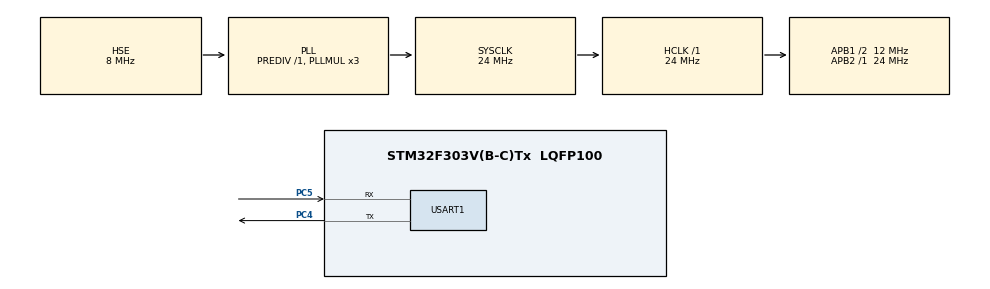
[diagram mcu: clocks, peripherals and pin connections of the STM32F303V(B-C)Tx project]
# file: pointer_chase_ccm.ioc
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Mcu.Family=STM32F3
Mcu.Name=STM32F303V(B-C)Tx
Mcu.Package=LQFP100
NVIC.PriorityGroup=NVIC_PRIORITYGROUP_4
NVIC.TIM2_IRQn=true\:0\:0\:false\:false\:true\:true\:true
PC4.Mode=Asynchronous
PC4.Signal=USART1_TX
PC5.Mode=Asynchronous
PC5.Signal=USART1_RX
PF0-OSC_IN.Mode=HSE-External-Oscillator
PF0-OSC_IN.Signal=RCC_OSC_IN
PF1-OSC_OUT.Mode=HSE-External-Oscillator
PF1-OSC_OUT.Signal=RCC_OSC_OUT
ProjectManager.HeapSize=0x200
ProjectManager.StackSize=0x400
ProjectManager.TargetToolchain=STM32CubeIDE
RCC.AHBFreq_Value=24000000
RCC.APB1CLKDivider=RCC_HCLK_DIV2
RCC.APB1Freq_Value=12000000
RCC.APB1TimFreq_Value=24000000
RCC.APB2Freq_Value=24000000
RCC.APB2TimFreq_Value=24000000
RCC.CortexFreq_Value=24000000
RCC.HCLKFreq_Value=24000000
RCC.HSE_VALUE=8000000
RCC.HSI_VALUE=8000000
RCC.LSE_VALUE=32768
RCC.PLLMUL=RCC_PLL_MUL3
RCC.PLLSourceVirtual=RCC_PLLSOURCE_HSE
RCC.SYSCLKFreq_VALUE=24000000
RCC.SYSCLKSourceVirtual=RCC_SYSCLKSOURCE_PLLCLK
RCC.USBFreq_Value=24000000
TIM2.AutoReloadPreload=TIM_AUTORELOAD_PRELOAD_DISABLE
TIM2.Period=(1000000-1)
TIM2.Prescaler=(24-1)
USART1.VirtualMode-Asynchronous=VM_ASYNC
VP_TIM2_VS_ClockSourceINT.Mode=Internal
board=custom

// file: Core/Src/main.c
/* USER CODE BEGIN Header */
/**
  ******************************************************************************
  * @file           : main.c
  * @brief          : Main program body
  ******************************************************************************
  * @attention
  *
  * <h2><center>&copy; Copyright (c) 2021 STMicroelectronics.
  * All rights reserved.</center></h2>
  *
  * This software component is licensed by ST under BSD 3-Clause license,
  * the "License"; You may not use this file except in compliance with the
  * License. You may obtain a copy of the License at:
  *                        opensource.org/licenses/BSD-3-Clause
  *
  ******************************************************************************
  */
/* USER CODE END Header */
#include "main.h"

/* USER CODE BEGIN PM */
TIM_HandleTypeDef htim2;

UART_HandleTypeDef huart1;

/*data size*/
#define POINTER_SIZE_2000

/*functions data*/
//#define FUNCTIONS_DATA_ON_FLASH
#define FUNCTIONS_DATA_ON_CCM

/*program allocation*/
#define PROGRAM_IN_CCM

/* USER CODE END PM */

TIM_HandleTypeDef htim2;

UART_HandleTypeDef huart1;

/* USER CODE BEGIN PV */
#ifdef PROGRAM_IN_CCM
  __attribute__((section(".ccmram")))
#endif
void pointer_chase( void * p0){

    void **this_pp = p0;
    for(int i = 0;i<1000;i++){
	  while(this_pp){
      this_pp = *this_pp;
	  }
    this_pp = p0;
  };

}

/* USER CODE END PV */

void SystemClock_Config(void);
static void MX_GPIO_Init(void);
static void MX_TIM2_Init(void);
static void MX_USART1_UART_Init(void);

/* USER CODE BEGIN 0 */

#ifdef POINTER_SIZE_100
#ifdef FUNCTIONS_DATA_ON_CCM
  __attribute__((section(".ccmramdata")))
#endif
#ifdef FUNCTIONS_DATA_ON_FLASH
  const
#endif
   void *
#ifdef FUNCTIONS_DATA_ON_FLASH
  const
#endif
  pointers[100] = {
  &pointers[1], &pointers[2], &pointers[3], &pointers[4], &pointers[5], &pointers[6], &pointers[7], &pointers[8], &pointers[9], &pointers[10], &pointers[11], &pointers[12], &pointers[13], &pointers[14], &pointers[15], &pointers[16], &pointers[17], &pointers[18], &pointers[19], &pointers[20], &pointers[21], &pointers[22], &pointers[23], &pointers[24], &pointers[25], &pointers[26], &pointers[27], &pointers[28], &pointers[29], &pointers[30], &pointers[31], &pointers[32], &pointers[33], &pointers[34], &pointers[35], &pointers[36], &pointers[37], &pointers[38], &pointers[39], &pointers[40], &pointers[41], &pointers[42], &pointers[43], &pointers[44], &pointers[45], &pointers[46], &pointers[47], &pointers[48], &pointers[49], &pointers[50],
  &pointers[51], &pointers[52], &pointers[53], &pointers[54], &pointers[55], &pointers[56], &pointers[57], &pointers[58], &pointers[59], &pointers[60], &pointers[61], &pointers[62], &pointers[63], &pointers[64], &pointers[65], &pointers[66], &pointers[67], &pointers[68], &pointers[69], &pointers[70], &pointers[71], &pointers[72], &pointers[73], &pointers[74], &pointers[75], &pointers[76], &pointers[77], &pointers[78], &pointers[79], &pointers[80], &pointers[81], &pointers[82], &pointers[83], &pointers[84], &pointers[85], &pointers[86], &pointers[87], &pointers[88], &pointers[89], &pointers[90], &pointers[91], &pointers[92], &pointers[93], &pointers[94], &pointers[95], &pointers[96], &pointers[97], &pointers[98], &pointers[99], NULL };

#endif

#ifdef POINTER_SIZE_200
#ifdef FUNCTIONS_DATA_ON_CCM
  __attribute__((section(".ccmramdata")))
#endif
#ifdef FUNCTIONS_DATA_ON_FLASH
  const
#endif
   void *
#ifdef FUNCTIONS_DATA_ON_FLASH
  const
#endif
  pointers[200] = {
  &pointers[1], &pointers[2], &pointers[3], &pointers[4], &pointers[5], &pointers[6], &pointers[7], &pointers[8], &pointers[9], &pointers[10], &pointers[11], &pointers[12], &pointers[13], &pointers[14], &pointers[15], &pointers[16], &pointers[17], &pointers[18], &pointers[19], &pointers[20], &pointers[21], &pointers[22], &pointers[23], &pointers[24], &pointers[25], &pointers[26], &pointers[27], &pointers[28], &pointers[29], &pointers[30], &pointers[31], &pointers[32], &pointers[33], &pointers[34], &pointers[35], &pointers[36], &pointers[37], &pointers[38], &pointers[39], &pointers[40], &pointers[41], &pointers[42], &pointers[43], &pointers[44], &pointers[45], &pointers[46], &pointers[47], &pointers[48], &pointers[49], &pointers[50],
  &pointers[51], &pointers[52], &pointers[53], &pointers[54], &pointers[55], &pointers[56], &pointers[57], &pointers[58], &pointers[59], &pointers[60], &pointers[61], &pointers[62], &pointers[63], &pointers[64], &pointers[65], &pointers[66], &pointers[67], &pointers[68], &pointers[69], &pointers[70], &pointers[71], &pointers[72], &pointers[73], &pointers[74], &pointers[75], &pointers[76], &pointers[77], &pointers[78], &pointers[79], &pointers[80], &pointers[81], &pointers[82], &pointers[83], &pointers[84], &pointers[85], &pointers[86], &pointers[87], &pointers[88], &pointers[89], &pointers[90], &pointers[91], &pointers[92], &pointers[93], &pointers[94], &pointers[95], &pointers[96], &pointers[97], &pointers[98], &pointers[99], &pointers[100],
  &pointers[101], &pointers[102], &pointers[103], &pointers[104], &pointers[105], &pointers[106], &pointers[107], &pointers[108], &pointers[109], &pointers[110], &pointers[111], &pointers[112], &pointers[113], &pointers[114], &pointers[115], &pointers[116], &pointers[117], &pointers[118], &pointers[119], &pointers[120], &pointers[121], &pointers[122], &pointers[123], &pointers[124], &pointers[125], &pointers[126], &pointers[127], &pointers[128], &pointers[129], &pointers[130], &pointers[131], &pointers[132], &pointers[133], &pointers[134], &pointers[135], &pointers[136], &pointers[137], &pointers[138], &pointers[139], &pointers[140], &pointers[141], &pointers[142], &pointers[143], &pointers[144], &pointers[145], &pointers[146], &pointers[147], &pointers[148], &pointers[149], &pointers[150],
  &pointers[151], &pointers[152], &pointers[153], &pointers[154], &pointers[155], &pointers[156], &pointers[157], &pointers[158], &pointers[159], &pointers[160], &pointers[161], &pointers[162], &pointers[163], &pointers[164], &pointers[165], &pointers[166], &pointers[167], &pointers[168], &pointers[169], &pointers[170], &pointers[171], &pointers[172], &pointers[173], &pointers[174], &pointers[175], &pointers[176], &pointers[177], &pointers[178], &pointers[179], &pointers[180], &pointers[181], &pointers[182], &pointers[183], &pointers[184], &pointers[185], &pointers[186], &pointers[187], &pointers[188], &pointers[189], &pointers[190], &pointers[191], &pointers[192], &pointers[193], &pointers[194], &pointers[195], &pointers[196], &pointers[197], &pointers[198], &pointers[199], NULL };
#endif

#ifdef POINTER_SIZE_300
#ifdef FUNCTIONS_DATA_ON_CCM
  __attribute__((section(".ccmramdata")))
#endif
#ifdef FUNCTIONS_DATA_ON_FLASH
  const
#endif
   void *
#ifdef FUNCTIONS_DATA_ON_FLASH
  const
#endif
  pointers[300] = {
  &pointers[1], &pointers[2], &pointers[3], &pointers[4], &pointers[5], &pointers[6], &pointers[7], &pointers[8], &pointers[9], &pointers[10], &pointers[11], &pointers[12], &pointers[13], &pointers[14], &pointers[15], &pointers[16], &pointers[17], &pointers[18], &pointers[19], &pointers[20], &pointers[21], &pointers[22], &pointers[23], &pointers[24], &pointers[25], &pointers[26], &pointers[27], &pointers[28], &pointers[29], &pointers[30], &pointers[31], &pointers[32], &pointers[33], &pointers[34], &pointers[35], &pointers[36], &pointers[37], &pointers[38], &pointers[39], &pointers[40], &pointers[41], &pointers[42], &pointers[43], &pointers[44], &pointers[45], &pointers[46], &pointers[47], &pointers[48], &pointers[49], &pointers[50],
  &pointers[51], &pointers[52], &pointers[53], &pointers[54], &pointers[55], &pointers[56], &pointers[57], &pointers[58], &pointers[59], &pointers[60], &pointers[61], &pointers[62], &pointers[63], &pointers[64], &pointers[65], &pointers[66], &pointers[67], &pointers[68], &pointers[69], &pointers[70], &pointers[71], &pointers[72], &pointers[73], &pointers[74], &pointers[75], &pointers[76], &pointers[77], &pointers[78], &pointers[79], &pointers[80], &pointers[81], &pointers[82], &pointers[83], &pointers[84], &pointers[85], &pointers[86], &pointers[87], &pointers[88], &pointers[89], &pointers[90], &pointers[91], &pointers[92], &pointers[93], &pointers[94], &pointers[95], &pointers[96], &pointers[97], &pointers[98], &pointers[99], &pointers[100],
  &pointers[101], &pointers[102], &pointers[103], &pointers[104], &pointers[105], &pointers[106], &pointers[107], &pointers[108], &pointers[109], &pointers[110], &pointers[111], &pointers[112], &pointers[113], &pointers[114], &pointers[115], &pointers[116], &pointers[117], &pointers[118], &pointers[119], &pointers[120], &pointers[121], &pointers[122], &pointers[123], &pointers[124], &pointers[125], &pointers[126], &pointers[127], &pointers[128], &pointers[129], &pointers[130], &pointers[131], &pointers[132], &pointers[133], &pointers[134], &pointers[135], &pointers[136], &pointers[137], &pointers[138], &pointers[139], &pointers[140], &pointers[141], &pointers[142], &pointers[143], &pointers[144], &pointers[145], &pointers[146], &pointers[147], &pointers[148], &pointers[149], &pointers[150],
  &pointers[151], &pointers[152], &pointers[153], &pointers[154], &pointers[155], &pointers[156], &pointers[157], &pointers[158], &pointers[159], &pointers[160], &pointers[161], &pointers[162], &pointers[163], &pointers[164], &pointers[165], &pointers[166], &pointers[167], &pointers[168], &pointers[169], &pointers[170], &pointers[171], &pointers[172], &pointers[173], &pointers[174], &pointers[175], &pointers[176], &pointers[177], &pointers[178], &pointers[179], &pointers[180], &pointers[181], &pointers[182], &pointers[183], &pointers[184], &pointers[185], &pointers[186], &pointers[187], &pointers[188], &pointers[189], &pointers[190], &pointers[191], &pointers[192], &pointers[193], &pointers[194], &pointers[195], &pointers[196], &pointers[197], &pointers[198], &pointers[199], &pointers[200],
  &pointers[201], &pointers[202], &pointers[203], &pointers[204], &pointers[205], &pointers[206], &pointers[207], &pointers[208], &pointers[209], &pointers[210], &pointers[211], &pointers[212], &pointers[213], &pointers[214], &pointers[215], &pointers[216], &pointers[217], &pointers[218], &pointers[219], &pointers[220], &pointers[221], &pointers[222], &pointers[223], &pointers[224], &pointers[225], &pointers[226], &pointers[227], &pointers[228], &pointers[229], &pointers[230], &pointers[231], &pointers[232], &pointers[233], &pointers[234], &pointers[235], &pointers[236], &pointers[237], &pointers[238], &pointers[239], &pointers[240], &pointers[241], &pointers[242], &pointers[243], &pointers[244], &pointers[245], &pointers[246], &pointers[247], &pointers[248], &pointers[249], &pointers[250],
  &pointers[251], &pointers[252], &pointers[253], &pointers[254], &pointers[255], &pointers[256], &pointers[257], &pointers[258], &pointers[259], &pointers[260], &pointers[261], &pointers[262], &pointers[263], &pointers[264], &pointers[265], &pointers[266], &pointers[267], &pointers[268], &pointers[269], &pointers[270], &pointers[271], &pointers[272], &pointers[273], &pointers[274], &pointers[275], &pointers[276], &pointers[277], &pointers[278], &pointers[279], &pointers[280], &pointers[281], &pointers[282], &pointers[283], &pointers[284], &pointers[285], &pointers[286], &pointers[287], &pointers[288], &pointers[289], &pointers[290], &pointers[291], &pointers[292], &pointers[293], &pointers[294], &pointers[295], &pointers[296], &pointers[297], &pointers[298], &pointers[299], NULL };
#endif

#ifdef POINTER_SIZE_400
#ifdef FUNCTIONS_DATA_ON_CCM
  __attribute__((section(".ccmramdata")))
#endif
#ifdef FUNCTIONS_DATA_ON_FLASH
  const
#endif
   void *
#ifdef FUNCTIONS_DATA_ON_FLASH
  const
#endif
  pointers[400] = {
  &pointers[1], &pointers[2], &pointers[3], &pointers[4], &pointers[5], &pointers[6], &pointers[7], &pointers[8], &pointers[9], &pointers[10], &pointers[11], &pointers[12], &pointers[13], &pointers[14], &pointers[15], &pointers[16], &pointers[17], &pointers[18], &pointers[19], &pointers[20], &pointers[21], &pointers[22], &pointers[23], &pointers[24], &pointers[25], &pointers[26], &pointers[27], &pointers[28], &pointers[29], &pointers[30], &pointers[31], &pointers[32], &pointers[33], &pointers[34], &pointers[35], &pointers[36], &pointers[37], &pointers[38], &pointers[39], &pointers[40], &pointers[41], &pointers[42], &pointers[43], &pointers[44], &pointers[45], &pointers[46], &pointers[47], &pointers[48], &pointers[49], &pointers[50],
  &pointers[51], &pointers[52], &pointers[53], &pointers[54], &pointers[55], &pointers[56], &pointers[57], &pointers[58], &pointers[59], &pointers[60], &pointers[61], &pointers[62], &pointers[63], &pointers[64], &pointers[65], &pointers[66], &pointers[67], &pointers[68], &pointers[69], &pointers[70], &pointers[71], &pointers[72], &pointers[73], &pointers[74], &pointers[75], &pointers[76], &pointers[77], &pointers[78], &pointers[79], &pointers[80], &pointers[81], &pointers[82], &pointers[83], &pointers[84], &pointers[85], &pointers[86], &pointers[87], &pointers[88], &pointers[89], &pointers[90], &pointers[91], &pointers[92], &pointers[93], &pointers[94], &pointers[95], &pointers[96], &pointers[97], &pointers[98], &pointers[99], &pointers[100],
  &pointers[101], &pointers[102], &pointers[103], &pointers[104], &pointers[105], &pointers[106], &pointers[107], &pointers[108], &pointers[109], &pointers[110], &pointers[111], &pointers[112], &pointers[113], &pointers[114], &pointers[115], &pointers[116], &pointers[117], &pointers[118], &pointers[119], &pointers[120], &pointers[121], &pointers[122], &pointers[123], &pointers[124], &pointers[125], &pointers[126], &pointers[127], &pointers[128], &pointers[129], &pointers[130], &pointers[131], &pointers[132], &pointers[133], &pointers[134], &pointers[135], &pointers[136], &pointers[137], &pointers[138], &pointers[139], &pointers[140], &pointers[141], &pointers[142], &pointers[143], &pointers[144], &pointers[145], &pointers[146], &pointers[147], &pointers[148], &pointers[149], &pointers[150],
  &pointers[151], &pointers[152], &pointers[153], &pointers[154], &pointers[155], &pointers[156], &pointers[157], &pointers[158], &pointers[159], &pointers[160], &pointers[161], &pointers[162], &pointers[163], &pointers[164], &pointers[165], &pointers[166], &pointers[167], &pointers[168], &pointers[169], &pointers[170], &pointers[171], &pointers[172], &pointers[173], &pointers[174], &pointers[175], &pointers[176], &pointers[177], &pointers[178], &pointers[179], &pointers[180], &pointers[181], &pointers[182], &pointers[183], &pointers[184], &pointers[185], &pointers[186], &pointers[187], &pointers[188], &pointers[189], &pointers[190], &pointers[191], &pointers[192], &pointers[193], &pointers[194], &pointers[195], &pointers[196], &pointers[197], &pointers[198], &pointers[199], &pointers[200],
  &pointers[201], &pointers[202], &pointers[203], &pointers[204], &pointers[205], &pointers[206], &pointers[207], &pointers[208], &pointers[209], &pointers[210], &pointers[211], &pointers[212], &pointers[213], &pointers[214], &pointers[215], &pointers[216], &pointers[217], &pointers[218], &pointers[219], &pointers[220], &pointers[221], &pointers[222], &pointers[223], &pointers[224], &pointers[225], &pointers[226], &pointers[227], &pointers[228], &pointers[229], &pointers[230], &pointers[231], &pointers[232], &pointers[233], &pointers[234], &pointers[235], &pointers[236], &pointers[237], &pointers[238], &pointers[239], &pointers[240], &pointers[241], &pointers[242], &pointers[243], &pointers[244], &pointers[245], &pointers[246], &pointers[247], &pointers[248], &pointers[249], &pointers[250],
  &pointers[251], &pointers[252], &pointers[253], &pointers[254], &pointers[255], &pointers[256], &pointers[257], &pointers[258], &pointers[259], &pointers[260], &pointers[261], &pointers[262], &pointers[263], &pointers[264], &pointers[265], &pointers[266], &pointers[267], &pointers[268], &pointers[269], &pointers[270], &pointers[271], &pointers[272], &pointers[273], &pointers[274], &pointers[275], &pointers[276], &pointers[277], &pointers[278], &pointers[279], &pointers[280], &pointers[281], &pointers[282], &pointers[283], &pointers[284], &pointers[285], &pointers[286], &pointers[287], &pointers[288], &pointers[289], &pointers[290], &pointers[291], &pointers[292], &pointers[293], &pointers[294], &pointers[295], &pointers[296], &pointers[297], &pointers[298], &pointers[299], &pointers[300],
  &pointers[301], &pointers[302], &pointers[303], &pointers[304], &pointers[305], &pointers[306], &pointers[307], &pointers[308], &pointers[309], &pointers[310], &pointers[311], &pointers[312], &pointers[313], &pointers[314], &pointers[315], &pointers[316], &pointers[317], &pointers[318], &pointers[319], &pointers[320], &pointers[321], &pointers[322], &pointers[323], &pointers[324], &pointers[325], &pointers[326], &pointers[327], &pointers[328], &pointers[329], &pointers[330], &pointers[331], &pointers[332], &pointers[333], &pointers[334], &pointers[335], &pointers[336], &pointers[337], &pointers[338], &pointers[339], &pointers[340], &pointers[341], &pointers[342], &pointers[343], &pointers[344], &pointers[345], &pointers[346], &pointers[347], &pointers[348], &pointers[349], &pointers[350],
  &pointers[351], &pointers[352], &pointers[353], &pointers[354], &pointers[355], &pointers[356], &pointers[357], &pointers[358], &pointers[359], &pointers[360], &pointers[361], &pointers[362], &pointers[363], &pointers[364], &pointers[365], &pointers[366], &pointers[367], &pointers[368], &pointers[369], &pointers[370], &pointers[371], &pointers[372], &pointers[373], &pointers[374], &pointers[375], &pointers[376], &pointers[377], &pointers[378], &pointers[379], &pointers[380], &pointers[381], &pointers[382], &pointers[383], &pointers[384], &pointers[385], &pointers[386], &pointers[387], &pointers[388], &pointers[389], &pointers[390], &pointers[391], &pointers[392], &pointers[393], &pointers[394], &pointers[395], &pointers[396], &pointers[397], &pointers[398], &pointers[399], NULL };
#endif

#ifdef POINTER_SIZE_500
#ifdef FUNCTIONS_DATA_ON_CCM
  __attribute__((section(".ccmramdata")))
#endif
#ifdef FUNCTIONS_DATA_ON_FLASH
  const
#endif
   void *
#ifdef FUNCTIONS_DATA_ON_FLASH
  const
#endif
  pointers[500] = {
  &pointers[1], &pointers[2], &pointers[3], &pointers[4], &pointers[5], &pointers[6], &pointers[7], &pointers[8], &pointers[9], &pointers[10], &pointers[11], &pointers[12], &pointers[13], &pointers[14], &pointers[15], &pointers[16], &pointers[17], &pointers[18], &pointers[19], &pointers[20], &pointers[21], &pointers[22], &pointers[23], &pointers[24], &pointers[25], &pointers[26], &pointers[27], &pointers[28], &pointers[29], &pointers[30], &pointers[31], &pointers[32], &pointers[33], &pointers[34], &pointers[35], &pointers[36], &pointers[37], &pointers[38], &pointers[39], &pointers[40], &pointers[41], &pointers[42], &pointers[43], &pointers[44], &pointers[45], &pointers[46], &pointers[47], &pointers[48], &pointers[49], &pointers[50],
  &pointers[51], &pointers[52], &pointers[53], &pointers[54], &pointers[55], &pointers[56], &pointers[57], &pointers[58], &pointers[59], &pointers[60], &pointers[61], &pointers[62], &pointers[63], &pointers[64], &pointers[65], &pointers[66], &pointers[67], &pointers[68], &pointers[69], &pointers[70], &pointers[71], &pointers[72], &pointers[73], &pointers[74], &pointers[75], &pointers[76], &pointers[77], &pointers[78], &pointers[79], &pointers[80], &pointers[81], &pointers[82], &pointers[83], &pointers[84], &pointers[85], &pointers[86], &pointers[87], &pointers[88], &pointers[89], &pointers[90], &pointers[91], &pointers[92], &pointers[93], &pointers[94], &pointers[95], &pointers[96], &pointers[97], &pointers[98], &pointers[99], &pointers[100],
  &pointers[101], &pointers[102], &pointers[103], &pointers[104], &pointers[105], &pointers[106], &pointers[107], &pointers[108], &pointers[109], &pointers[110], &pointers[111], &pointers[112], &pointers[113], &pointers[114], &pointers[115], &pointers[116], &pointers[117], &pointers[118], &pointers[119], &pointers[120], &pointers[121], &pointers[122], &pointers[123], &pointers[124], &pointers[125], &pointers[126], &pointers[127], &pointers[128], &pointers[129], &pointers[130], &pointers[131], &pointers[132], &pointers[133], &pointers[134], &pointers[135], &pointers[136], &pointers[137], &pointers[138], &pointers[139], &pointers[140], &pointers[141], &pointers[142], &pointers[143], &pointers[144], &pointers[145], &pointers[146], &pointers[147], &pointers[148], &pointers[149], &pointers[150],
  &pointers[151], &pointers[152], &pointers[153], &pointers[154], &pointers[155], &pointers[156], &pointers[157], &pointers[158], &pointers[159], &pointers[160], &pointers[161], &pointers[162], &pointers[163], &pointers[164], &pointers[165], &pointers[166], &pointers[167], &pointers[168], &pointers[169], &pointers[170], &pointers[171], &pointers[172], &pointers[173], &pointers[174], &pointers[175], &pointers[176], &pointers[177], &pointers[178], &pointers[179], &pointers[180], &pointers[181], &pointers[182], &pointers[183], &pointers[184], &pointers[185], &pointers[186], &pointers[187], &pointers[188], &pointers[189], &pointers[190], &pointers[191], &pointers[192], &pointers[193], &pointers[194], &pointers[195], &pointers[196], &pointers[197], &pointers[198], &pointers[199], &pointers[200],
  &pointers[201], &pointers[202], &pointers[203], &pointers[204], &pointers[205], &pointers[206], &pointers[207], &pointers[208], &pointers[209], &pointers[210], &pointers[211], &pointers[212], &pointers[213], &pointers[214], &pointers[215], &pointers[216], &pointers[217], &pointers[218], &pointers[219], &pointers[220], &pointers[221], &pointers[222], &pointers[223], &pointers[224], &pointers[225], &pointers[226], &pointers[227], &pointers[228], &pointers[229], &pointers[230], &pointers[231], &pointers[232], &pointers[233], &pointers[234], &pointers[235], &pointers[236], &pointers[237], &pointers[238], &pointers[239], &pointers[240], &pointers[241], &pointers[242], &pointers[243], &pointers[244], &pointers[245], &pointers[246], &pointers[247], &pointers[248], &pointers[249], &pointers[250],
  &pointers[251], &pointers[252], &pointers[253], &pointers[254], &pointers[255], &pointers[256], &pointers[257], &pointers[258], &pointers[259], &pointers[260], &pointers[261], &pointers[262], &pointers[263], &pointers[264], &pointers[265], &pointers[266], &pointers[267], &pointers[268], &pointers[269], &pointers[270], &pointers[271], &pointers[272], &pointers[273], &pointers[274], &pointers[275], &pointers[276], &pointers[277], &pointers[278], &pointers[279], &pointers[280], &pointers[281], &pointers[282], &pointers[283], &pointers[284], &pointers[285], &pointers[286], &pointers[287], &pointers[288], &pointers[289], &pointers[290], &pointers[291], &pointers[292], &pointers[293], &pointers[294], &pointers[295], &pointers[296], &pointers[297], &pointers[298], &pointers[299], &pointers[300],
  &pointers[301], &pointers[302], &pointers[303], &pointers[304], &pointers[305], &pointers[306], &pointers[307], &pointers[308], &pointers[309], &pointers[310], &pointers[311], &pointers[312], &pointers[313], &pointers[314], &pointers[315], &pointers[316], &pointers[317], &pointers[318], &pointers[319], &pointers[320], &pointers[321], &pointers[322], &pointers[323], &pointers[324], &pointers[325], &pointers[326], &pointers[327], &pointers[328], &pointers[329], &pointers[330], &pointers[331], &pointers[332], &pointers[333], &pointers[334], &pointers[335], &pointers[336], &pointers[337], &pointers[338], &pointers[339], &pointers[340], &pointers[341], &pointers[342], &pointers[343], &pointers[344], &pointers[345], &pointers[346], &pointers[347], &pointers[348], &pointers[349], &pointers[350],
  &pointers[351], &pointers[352], &pointers[353], &pointers[354], &pointers[355], &pointers[356], &pointers[357], &pointers[358], &pointers[359], &pointers[360], &pointers[361], &pointers[362], &pointers[363], &pointers[364], &pointers[365], &pointers[366], &pointers[367], &pointers[368], &pointers[369], &pointers[370], &pointers[371], &pointers[372], &pointers[373], &pointers[374], &pointers[375], &pointers[376], &pointers[377], &pointers[378], &pointers[379], &pointers[380], &pointers[381], &pointers[382], &pointers[383], &pointers[384], &pointers[385], &pointers[386], &pointers[387], &pointers[388], &pointers[389], &pointers[390], &pointers[391], &pointers[392], &pointers[393], &pointers[394], &pointers[395], &pointers[396], &pointers[397], &pointers[398], &pointers[399], &pointers[400],
  &pointers[401], &pointers[402], &pointers[403], &pointers[404], &pointers[405], &pointers[406], &pointers[407], &pointers[408], &pointers[409], &pointers[410], &pointers[411], &pointers[412], &pointers[413], &pointers[414], &pointers[415], &pointers[416], &pointers[417], &pointers[418], &pointers[419], &pointers[420], &pointers[421], &pointers[422], &pointers[423], &pointers[424], &pointers[425], &pointers[426], &pointers[427], &pointers[428], &pointers[429], &pointers[430], &pointers[431], &pointers[432], &pointers[433], &pointers[434], &pointers[435], &pointers[436], &pointers[437], &pointers[438], &pointers[439], &pointers[440], &pointers[441], &pointers[442], &pointers[443], &pointers[444], &pointers[445], &pointers[446], &pointers[447], &pointers[448], &pointers[449], &pointers[450],
  &pointers[451], &pointers[452], &pointers[453], &pointers[454], &pointers[455], &pointers[456], &pointers[457], &pointers[458], &pointers[459], &pointers[460], &pointers[461], &pointers[462], &pointers[463], &pointers[464], &pointers[465], &pointers[466], &pointers[467], &pointers[468], &pointers[469], &pointers[470], &pointers[471], &pointers[472], &pointers[473], &pointers[474], &pointers[475], &pointers[476], &pointers[477], &pointers[478], &pointers[479], &pointers[480], &pointers[481], &pointers[482], &pointers[483], &pointers[484], &pointers[485], &pointers[486], &pointers[487], &pointers[488], &pointers[489], &pointers[490], &pointers[491], &pointers[492], &pointers[493], &pointers[494], &pointers[495], &pointers[496], &pointers[497], &pointers[498], &pointers[499], NULL };
#endif

#ifdef POINTER_SIZE_750
#ifdef FUNCTIONS_DATA_ON_CCM
  __attribute__((section(".ccmramdata")))
#endif
#ifdef FUNCTIONS_DATA_ON_FLASH
  const
#endif
   void *
#ifdef FUNCTIONS_DATA_ON_FLASH
  const
#endif
  pointers[750] = {
  &pointers[1], &pointers[2], &pointers[3], &pointers[4], &pointers[5], &pointers[6], &pointers[7], &pointers[8], &pointers[9], &pointers[10], &pointers[11], &pointers[12], &pointers[13], &pointers[14], &pointers[15], &pointers[16], &pointers[17], &pointers[18], &pointers[19], &pointers[20], &pointers[21], &pointers[22], &pointers[23], &pointers[24], &pointers[25], &pointers[26], &pointers[27], &pointers[28], &pointers[29], &pointers[30], &pointers[31], &pointers[32], &pointers[33], &pointers[34], &pointers[35], &pointers[36], &pointers[37], &pointers[38], &pointers[39], &pointers[40], &pointers[41], &pointers[42], &pointers[43], &pointers[44], &pointers[45], &pointers[46], &pointers[47], &pointers[48], &pointers[49], &pointers[50],
  &pointers[51], &pointers[52], &pointers[53], &pointers[54], &pointers[55], &pointers[56], &pointers[57], &pointers[58], &pointers[59], &pointers[60], &pointers[61], &pointers[62], &pointers[63], &pointers[64], &pointers[65], &pointers[66], &pointers[67], &pointers[68], &pointers[69], &pointers[70], &pointers[71], &pointers[72], &pointers[73], &pointers[74], &pointers[75], &pointers[76], &pointers[77], &pointers[78], &pointers[79], &pointers[80], &pointers[81], &pointers[82], &pointers[83], &pointers[84], &pointers[85], &pointers[86], &pointers[87], &pointers[88], &pointers[89], &pointers[90], &pointers[91], &pointers[92], &pointers[93], &pointers[94], &pointers[95], &pointers[96], &pointers[97], &pointers[98], &pointers[99], &pointers[100],
  &pointers[101], &pointers[102], &pointers[103], &pointers[104], &pointers[105], &pointers[106], &pointers[107], &pointers[108], &pointers[109], &pointers[110], &pointers[111], &pointers[112], &pointers[113], &pointers[114], &pointers[115], &pointers[116], &pointers[117], &pointers[118], &pointers[119], &pointers[120], &pointers[121], &pointers[122], &pointers[123], &pointers[124], &pointers[125], &pointers[126], &pointers[127], &pointers[128], &pointers[129], &pointers[130], &pointers[131], &pointers[132], &pointers[133], &pointers[134], &pointers[135], &pointers[136], &pointers[137], &pointers[138], &pointers[139], &pointers[140], &pointers[141], &pointers[142], &pointers[143], &pointers[144], &pointers[145], &pointers[146], &pointers[147], &pointers[148], &pointers[149], &pointers[150],
  &pointers[151], &pointers[152], &pointers[153], &pointers[154], &pointers[155], &pointers[156], &pointers[157], &pointers[158], &pointers[159], &pointers[160], &pointers[161], &pointers[162], &pointers[163], &pointers[164], &pointers[165], &pointers[166], &pointers[167], &pointers[168], &pointers[169], &pointers[170], &pointers[171], &pointers[172], &pointers[173], &pointers[174], &pointers[175], &pointers[176], &pointers[177], &pointers[178], &pointers[179], &pointers[180], &pointers[181], &pointers[182], &pointers[183], &pointers[184], &pointers[185], &pointers[186], &pointers[187], &pointers[188], &pointers[189], &pointers[190], &pointers[191], &pointers[192], &pointers[193], &pointers[194], &pointers[195], &pointers[196], &pointers[197], &pointers[198], &pointers[199], &pointers[200],
  &pointers[201], &pointers[202], &pointers[203], &pointers[204], &pointers[205], &pointers[206], &pointers[207], &pointers[208], &pointers[209], &pointers[210], &pointers[211], &pointers[212], &pointers[213], &pointers[214], &pointers[215], &pointers[216], &pointers[217], &pointers[218], &pointers[219], &pointers[220], &pointers[221], &pointers[222], &pointers[223], &pointers[224], &pointers[225], &pointers[226], &pointers[227], &pointers[228], &pointers[229], &pointers[230], &pointers[231], &pointers[232], &pointers[233], &pointers[234], &pointers[235], &pointers[236], &pointers[237], &pointers[238], &pointers[239], &pointers[240], &pointers[241], &pointers[242], &pointers[243], &pointers[244], &pointers[245], &pointers[246], &pointers[247], &pointers[248], &pointers[249], &pointers[250],
  &pointers[251], &pointers[252], &pointers[253], &pointers[254], &pointers[255], &pointers[256], &pointers[257], &pointers[258], &pointers[259], &pointers[260], &pointers[261], &pointers[262], &pointers[263], &pointers[264], &pointers[265], &pointers[266], &pointers[267], &pointers[268], &pointers[269], &pointers[270], &pointers[271], &pointers[272], &pointers[273], &pointers[274], &pointers[275], &pointers[276], &pointers[277], &pointers[278], &pointers[279], &pointers[280], &pointers[281], &pointers[282], &pointers[283], &pointers[284], &pointers[285], &pointers[286], &pointers[287], &pointers[288], &pointers[289], &pointers[290], &pointers[291], &pointers[292], &pointers[293], &pointers[294], &pointers[295], &pointers[296], &pointers[297], &pointers[298], &pointers[299], &pointers[300],
  &pointers[301], &pointers[302], &pointers[303], &pointers[304], &pointers[305], &pointers[306], &pointers[307], &pointers[308], &pointers[309], &pointers[310], &pointers[311], &pointers[312], &pointers[313], &pointers[314], &pointers[315], &pointers[316], &pointers[317], &pointers[318], &pointers[319], &pointers[320], &pointers[321], &pointers[322], &pointers[323], &pointers[324], &pointers[325], &pointers[326], &pointers[327], &pointers[328], &pointers[329], &pointers[330], &pointers[331], &pointers[332], &pointers[333], &pointers[334], &pointers[335], &pointers[336], &pointers[337], &pointers[338], &pointers[339], &pointers[340], &pointers[341], &pointers[342], &pointers[343], &pointers[344], &pointers[345], &pointers[346], &pointers[347], &pointers[348], &pointers[349], &pointers[350],
  &pointers[351], &pointers[352], &pointers[353], &pointers[354], &pointers[355], &pointers[356], &pointers[357], &pointers[358], &pointers[359], &pointers[360], &pointers[361], &pointers[362], &pointers[363], &pointers[364], &pointers[365], &pointers[366], &pointers[367], &pointers[368], &pointers[369], &pointers[370], &pointers[371], &pointers[372], &pointers[373], &pointers[374], &pointers[375], &pointers[376], &pointers[377], &pointers[378], &pointers[379], &pointers[380], &pointers[381], &pointers[382], &pointers[383], &pointers[384], &pointers[385], &pointers[386], &pointers[387], &pointers[388], &pointers[389], &pointers[390], &pointers[391], &pointers[392], &pointers[393], &pointers[394], &pointers[395], &pointers[396], &pointers[397], &pointers[398], &pointers[399], &pointers[400],
  &pointers[401], &pointers[402], &pointers[403], &pointers[404], &pointers[405], &pointers[406], &pointers[407], &pointers[408], &pointers[409], &pointers[410], &pointers[411], &pointers[412], &pointers[413], &pointers[414], &pointers[415], &pointers[416], &pointers[417], &pointers[418], &pointers[419], &pointers[420], &pointers[421], &pointers[422], &pointers[423], &pointers[424], &pointers[425], &pointers[426], &pointers[427], &pointers[428], &pointers[429], &pointers[430], &pointers[431], &pointers[432], &pointers[433], &pointers[434], &pointers[435], &pointers[436], &pointers[437], &pointers[438], &pointers[439], &pointers[440], &pointers[441], &pointers[442], &pointers[443], &pointers[444], &pointers[445], &pointers[446], &pointers[447], &pointers[448], &pointers[449], &pointers[450],
  &pointers[451], &pointers[452], &pointers[453], &pointers[454], &pointers[455], &pointers[456], &pointers[457], &pointers[458], &pointers[459], &pointers[460], &pointers[461], &pointers[462], &pointers[463], &pointers[464], &pointers[465], &pointers[466], &pointers[467], &pointers[468], &pointers[469], &pointers[470], &pointers[471], &pointers[472], &pointers[473], &pointers[474], &pointers[475], &pointers[476], &pointers[477], &pointers[478], &pointers[479], &pointers[480], &pointers[481], &pointers[482], &pointers[483], &pointers[484], &pointers[485], &pointers[486], &pointers[487], &pointers[488], &pointers[489], &pointers[490], &pointers[491], &pointers[492], &pointers[493], &pointers[494], &pointers[495], &pointers[496], &pointers[497], &pointers[498], &pointers[499], &pointers[500],
  &pointers[501], &pointers[502], &pointers[503], &pointers[504], &pointers[505], &pointers[506], &pointers[507], &pointers[508], &pointers[509], &pointers[510], &pointers[511], &pointers[512], &pointers[513], &pointers[514], &pointers[515], &pointers[516], &pointers[517], &pointers[518], &pointers[519], &pointers[520], &pointers[521], &pointers[522], &pointers[523], &pointers[524], &pointers[525], &pointers[526], &pointers[527], &pointers[528], &pointers[529], &pointers[530], &pointers[531], &pointers[532], &pointers[533], &pointers[534], &pointers[535], &pointers[536], &pointers[537], &pointers[538], &pointers[539], &pointers[540], &pointers[541], &pointers[542], &pointers[543], &pointers[544], &pointers[545], &pointers[546], &pointers[547], &pointers[548], &pointers[549], &pointers[550],
  &pointers[551], &pointers[552], &pointers[553], &pointers[554], &pointers[555], &pointers[556], &pointers[557], &pointers[558], &pointers[559], &pointers[560], &pointers[561], &pointers[562], &pointers[563], &pointers[564], &pointers[565], &pointers[566], &pointers[567], &pointers[568], &pointers[569], &pointers[570], &pointers[571], &pointers[572], &pointers[573], &pointers[574], &pointers[575], &pointers[576], &pointers[577], &pointers[578], &pointers[579], &pointers[580], &pointers[581], &pointers[582], &pointers[583], &pointers[584], &pointers[585], &pointers[586], &pointers[587], &pointers[588], &pointers[589], &pointers[590], &pointers[591], &pointers[592], &pointers[593], &pointers[594], &pointers[595], &pointers[596], &pointers[597], &pointers[598], &pointers[599], &pointers[600],
  &pointers[601], &pointers[602], &pointers[603], &pointers[604], &pointers[605], &pointers[606], &pointers[607], &pointers[608], &pointers[609], &pointers[610], &pointers[611], &pointers[612], &pointers[613], &pointers[614], &pointers[615], &pointers[616], &pointers[617], &pointers[618], &pointers[619], &pointers[620], &pointers[621], &pointers[622], &pointers[623], &pointers[624], &pointers[625], &pointers[626], &pointers[627], &pointers[628], &pointers[629], &pointers[630], &pointers[631], &pointers[632], &pointers[633], &pointers[634], &pointers[635], &pointers[636], &pointers[637], &pointers[638], &pointers[639], &pointers[640], &pointers[641], &pointers[642], &pointers[643], &pointers[644], &pointers[645], &pointers[646], &pointers[647], &pointers[648], &pointers[649], &pointers[650],
  &pointers[651], &pointers[652], &pointers[653], &pointers[654], &pointers[655], &pointers[656], &pointers[657], &pointers[658], &pointers[659], &pointers[660], &pointers[661], &pointers[662], &pointers[663], &pointers[664], &pointers[665], &pointers[666], &pointers[667], &pointers[668], &pointers[669], &pointers[670], &pointers[671], &pointers[672], &pointers[673], &pointers[674], &pointers[675], &pointers[676], &pointers[677], &pointers[678], &pointers[679], &pointers[680], &pointers[681], &pointers[682], &pointers[683], &pointers[684], &pointers[685], &pointers[686], &pointers[687], &pointers[688], &pointers[689], &pointers[690], &pointers[691], &pointers[692], &pointers[693], &pointers[694], &pointers[695], &pointers[696], &pointers[697], &pointers[698], &pointers[699], &pointers[700],
  &pointers[701], &pointers[702], &pointers[703], &pointers[704], &pointers[705], &pointers[706], &pointers[707], &pointers[708], &pointers[709], &pointers[710], &pointers[711], &pointers[712], &pointers[713], &pointers[714], &pointers[715], &pointers[716], &pointers[717], &pointers[718], &pointers[719], &pointers[720], &pointers[721], &pointers[722], &pointers[723], &pointers[724], &pointers[725], &pointers[726], &pointers[727], &pointers[728], &pointers[729], &pointers[730], &pointers[731], &pointers[732], &pointers[733], &pointers[734], &pointers[735], &pointers[736], &pointers[737], &pointers[738], &pointers[739], &pointers[740], &pointers[741], &pointers[742], &pointers[743], &pointers[744], &pointers[745], &pointers[746], &pointers[747], &pointers[748], &pointers[749], NULL };

#endif

#ifdef POINTER_SIZE_1000
#ifdef FUNCTIONS_DATA_ON_CCM
  __attribute__((section(".ccmramdata")))
#endif

#ifdef FUNCTIONS_DATA_ON_FLASH
  const
#endif
   void *
#ifdef FUNCTIONS_DATA_ON_FLASH
  const
#endif
  pointers[1000] = {
  &pointers[1], &pointers[2], &pointers[3], &pointers[4], &pointers[5], &pointers[6], &pointers[7], &pointers[8], &pointers[9], &pointers[10], &pointers[11], &pointers[12], &pointers[13], &pointers[14], &pointers[15], &pointers[16], &pointers[17], &pointers[18], &pointers[19], &pointers[20], &pointers[21], &pointers[22], &pointers[23], &pointers[24], &pointers[25], &pointers[26], &pointers[27], &pointers[28], &pointers[29], &pointers[30], &pointers[31], &pointers[32], &pointers[33], &pointers[34], &pointers[35], &pointers[36], &pointers[37], &pointers[38], &pointers[39], &pointers[40], &pointers[41], &pointers[42], &pointers[43], &pointers[44], &pointers[45], &pointers[46], &pointers[47], &pointers[48], &pointers[49], &pointers[50],
  &pointers[51], &pointers[52], &pointers[53], &pointers[54], &pointers[55], &pointers[56], &pointers[57], &pointers[58], &pointers[59], &pointers[60], &pointers[61], &pointers[62], &pointers[63], &pointers[64], &pointers[65], &pointers[66], &pointers[67], &pointers[68], &pointers[69], &pointers[70], &pointers[71], &pointers[72], &pointers[73], &pointers[74], &pointers[75], &pointers[76], &pointers[77], &pointers[78], &pointers[79], &pointers[80], &pointers[81], &pointers[82], &pointers[83], &pointers[84], &pointers[85], &pointers[86], &pointers[87], &pointers[88], &pointers[89], &pointers[90], &pointers[91], &pointers[92], &pointers[93], &pointers[94], &pointers[95], &pointers[96], &pointers[97], &pointers[98], &pointers[99], &pointers[100],
  &pointers[101], &pointers[102], &pointers[103], &pointers[104], &pointers[105], &pointers[106], &pointers[107], &pointers[108], &pointers[109], &pointers[110], &pointers[111], &pointers[112], &pointers[113], &pointers[114], &pointers[115], &pointers[116], &pointers[117], &pointers[118], &pointers[119], &pointers[120], &pointers[121], &pointers[122], &pointers[123], &pointers[124], &pointers[125], &pointers[126], &pointers[127], &pointers[128], &pointers[129], &pointers[130], &pointers[131], &pointers[132], &pointers[133], &pointers[134], &pointers[135], &pointers[136], &pointers[137], &pointers[138], &pointers[139], &pointers[140], &pointers[141], &pointers[142], &pointers[143], &pointers[144], &pointers[145], &pointers[146], &pointers[147], &pointers[148], &pointers[149], &pointers[150],
  &pointers[151], &pointers[152], &pointers[153], &pointers[154], &pointers[155], &pointers[156], &pointers[157], &pointers[158], &pointers[159], &pointers[160], &pointers[161], &pointers[162], &pointers[163], &pointers[164], &pointers[165], &pointers[166], &pointers[167], &pointers[168], &pointers[169], &pointers[170], &pointers[171], &pointers[172], &pointers[173], &pointers[174], &pointers[175], &pointers[176], &pointers[177], &pointers[178], &pointers[179], &pointers[180], &pointers[181], &pointers[182], &pointers[183], &pointers[184], &pointers[185], &pointers[186], &pointers[187], &pointers[188], &pointers[189], &pointers[190], &pointers[191], &pointers[192], &pointers[193], &pointers[194], &pointers[195], &pointers[196], &pointers[197], &pointers[198], &pointers[199], &pointers[200],
  &pointers[201], &pointers[202], &pointers[203], &pointers[204], &pointers[205], &pointers[206], &pointers[207], &pointers[208], &pointers[209], &pointers[210], &pointers[211], &pointers[212], &pointers[213], &pointers[214], &pointers[215], &pointers[216], &pointers[217], &pointers[218], &pointers[219], &pointers[220], &pointers[221], &pointers[222], &pointers[223], &pointers[224], &pointers[225], &pointers[226], &pointers[227], &pointers[228], &pointers[229], &pointers[230], &pointers[231], &pointers[232], &pointers[233], &pointers[234], &pointers[235], &pointers[236], &pointers[237], &pointers[238], &pointers[239], &pointers[240], &pointers[241], &pointers[242], &pointers[243], &pointers[244], &pointers[245], &pointers[246], &pointers[247], &pointers[248], &pointers[249], &pointers[250],
  &pointers[251], &pointers[252], &pointers[253], &pointers[254], &pointers[255], &pointers[256], &pointers[257], &pointers[258], &pointers[259], &pointers[260], &pointers[261], &pointers[262], &pointers[263], &pointers[264], &pointers[265], &pointers[266], &pointers[267], &pointers[268], &pointers[269], &pointers[270], &pointers[271], &pointers[272], &pointers[273], &pointers[274], &pointers[275], &pointers[276], &pointers[277], &pointers[278], &pointers[279], &pointers[280], &pointers[281], &pointers[282], &pointers[283], &pointers[284], &pointers[285], &pointers[286], &pointers[287], &pointers[288], &pointers[289], &pointers[290], &pointers[291], &pointers[292], &pointers[293], &pointers[294], &pointers[295], &pointers[296], &pointers[297], &pointers[298], &pointers[299], &pointers[300],
  &pointers[301], &pointers[302], &pointers[303], &pointers[304], &pointers[305], &pointers[306], &pointers[307], &pointers[308], &pointers[309], &pointers[310], &pointers[311], &pointers[312], &pointers[313], &pointers[314], &pointers[315], &pointers[316], &pointers[317], &pointers[318], &pointers[319], &pointers[320], &pointers[321], &pointers[322], &pointers[323], &pointers[324], &pointers[325], &pointers[326], &pointers[327], &pointers[328], &pointers[329], &pointers[330], &pointers[331], &pointers[332], &pointers[333], &pointers[334], &pointers[335], &pointers[336], &pointers[337], &pointers[338], &pointers[339], &pointers[340], &pointers[341], &pointers[342], &pointers[343], &pointers[344], &pointers[345], &pointers[346], &pointers[347], &pointers[348], &pointers[349], &pointers[350],
  &pointers[351], &pointers[352], &pointers[353], &pointers[354], &pointers[355], &pointers[356], &pointers[357], &pointers[358], &pointers[359], &pointers[360], &pointers[361], &pointers[362], &pointers[363], &pointers[364], &pointers[365], &pointers[366], &pointers[367], &pointers[368], &pointers[369], &pointers[370], &pointers[371], &pointers[372], &pointers[373], &pointers[374], &pointers[375], &pointers[376], &pointers[377], &pointers[378], &pointers[379], &pointers[380], &pointers[381], &pointers[382], &pointers[383], &pointers[384], &pointers[385], &pointers[386], &pointers[387], &pointers[388], &pointers[389], &pointers[390], &pointers[391], &pointers[392], &pointers[393], &pointers[394], &pointers[395], &pointers[396], &pointers[397], &pointers[398], &pointers[399], &pointers[400],
  &pointers[401], &pointers[402], &pointers[403], &pointers[404], &pointers[405], &pointers[406], &pointers[407], &pointers[408], &pointers[409], &pointers[410], &pointers[411], &pointers[412], &pointers[413], &pointers[414], &pointers[415], &pointers[416], &pointers[417], &pointers[418], &pointers[419], &pointers[420], &pointers[421], &pointers[422], &pointers[423], &pointers[424], &pointers[425], &pointers[426], &pointers[427], &pointers[428], &pointers[429], &pointers[430], &pointers[431], &pointers[432], &pointers[433], &pointers[434], &pointers[435], &pointers[436], &pointers[437], &pointers[438], &pointers[439], &pointers[440], &pointers[441], &pointers[442], &pointers[443], &pointers[444], &pointers[445], &pointers[446], &pointers[447], &pointers[448], &pointers[449], &pointers[450],
  &pointers[451], &pointers[452], &pointers[453], &pointers[454], &pointers[455], &pointers[456], &pointers[457], &pointers[458], &pointers[459], &pointers[460], &pointers[461], &pointers[462], &pointers[463], &pointers[464], &pointers[465], &pointers[466], &pointers[467], &pointers[468], &pointers[469], &pointers[470], &pointers[471], &pointers[472], &pointers[473], &pointers[474], &pointers[475], &pointers[476], &pointers[477], &pointers[478], &pointers[479], &pointers[480], &pointers[481], &pointers[482], &pointers[483], &pointers[484], &pointers[485], &pointers[486], &pointers[487], &pointers[488], &pointers[489], &pointers[490], &pointers[491], &pointers[492], &pointers[493], &pointers[494], &pointers[495], &pointers[496], &pointers[497], &pointers[498], &pointers[499], &pointers[500],
  &pointers[501], &pointers[502], &pointers[503], &pointers[504], &pointers[505], &pointers[506], &pointers[507], &pointers[508], &pointers[509], &pointers[510], &pointers[511], &pointers[512], &pointers[513], &pointers[514], &pointers[515], &pointers[516], &pointers[517], &pointers[518], &pointers[519], &pointers[520], &pointers[521], &pointers[522], &pointers[523], &pointers[524], &pointers[525], &pointers[526], &pointers[527], &pointers[528], &pointers[529], &pointers[530], &pointers[531], &pointers[532], &pointers[533], &pointers[534], &pointers[535], &pointers[536], &pointers[537], &pointers[538], &pointers[539], &pointers[540], &pointers[541], &pointers[542], &pointers[543], &pointers[544], &pointers[545], &pointers[546], &pointers[547], &pointers[548], &pointers[549], &pointers[550],
  &pointers[551], &pointers[552], &pointers[553], &pointers[554], &pointers[555], &pointers[556], &pointers[557], &pointers[558], &pointers[559], &pointers[560], &pointers[561], &pointers[562], &pointers[563], &pointers[564], &pointers[565], &pointers[566], &pointers[567], &pointers[568], &pointers[569], &pointers[570], &pointers[571], &pointers[572], &pointers[573], &pointers[574], &pointers[575], &pointers[576], &pointers[577], &pointers[578], &pointers[579], &pointers[580], &pointers[581], &pointers[582], &pointers[583], &pointers[584], &pointers[585], &pointers[586], &pointers[587], &pointers[588], &pointers[589], &pointers[590], &pointers[591], &pointers[592], &pointers[593], &pointers[594], &pointers[595], &pointers[596], &pointers[597], &pointers[598], &pointers[599], &pointers[600],
  &pointers[601], &pointers[602], &pointers[603], &pointers[604], &pointers[605], &pointers[606], &pointers[607], &pointers[608], &pointers[609], &pointers[610], &pointers[611], &pointers[612], &pointers[613], &pointers[614], &pointers[615], &pointers[616], &pointers[617], &pointers[618], &pointers[619], &pointers[620], &pointers[621], &pointers[622], &pointers[623], &pointers[624], &pointers[625], &pointers[626], &pointers[627], &pointers[628], &pointers[629], &pointers[630], &pointers[631], &pointers[632], &pointers[633], &pointers[634], &pointers[635], &pointers[636], &pointers[637], &pointers[638], &pointers[639], &pointers[640], &pointers[641], &pointers[642], &pointers[643], &pointers[644], &pointers[645], &pointers[646], &pointers[647], &pointers[648], &pointers[649], &pointers[650],
  &pointers[651], &pointers[652], &pointers[653], &pointers[654], &pointers[655], &pointers[656], &pointers[657], &pointers[658], &pointers[659], &pointers[660], &pointers[661], &pointers[662], &pointers[663], &pointers[664], &pointers[665], &pointers[666], &pointers[667], &pointers[668], &pointers[669], &pointers[670], &pointers[671], &pointers[672], &pointers[673], &pointers[674], &pointers[675], &pointers[676], &pointers[677], &pointers[678], &pointers[679], &pointers[680], &pointers[681], &pointers[682], &pointers[683], &pointers[684], &pointers[685], &pointers[686], &pointers[687], &pointers[688], &pointers[689], &pointers[690], &pointers[691], &pointers[692], &pointers[693], &pointers[694], &pointers[695], &pointers[696], &pointers[697], &pointers[698], &pointers[699], &pointers[700],
  &pointers[701], &pointers[702], &pointers[703], &pointers[704], &pointers[705], &pointers[706], &pointers[707], &pointers[708], &pointers[709], &pointers[710], &pointers[711], &pointers[712], &pointers[713], &pointers[714], &pointers[715], &pointers[716], &pointers[717], &pointers[718], &pointers[719], &pointers[720], &pointers[721], &pointers[722], &pointers[723], &pointers[724], &pointers[725], &pointers[726], &pointers[727], &pointers[728], &pointers[729], &pointers[730], &pointers[731], &pointers[732], &pointers[733], &pointers[734], &pointers[735], &pointers[736], &pointers[737], &pointers[738], &pointers[739], &pointers[740], &pointers[741], &pointers[742], &pointers[743], &pointers[744], &pointers[745], &pointers[746], &pointers[747], &pointers[748], &pointers[749], &pointers[750],
  &pointers[751], &pointers[752], &pointers[753], &pointers[754], &pointers[755], &pointers[756], &pointers[757], &pointers[758], &pointers[759], &pointers[760], &pointers[761], &pointers[762], &pointers[763], &pointers[764], &pointers[765], &pointers[766], &pointers[767], &pointers[768], &pointers[769], &pointers[770], &pointers[771], &pointers[772], &pointers[773], &pointers[774], &pointers[775], &pointers[776], &pointers[777], &pointers[778], &pointers[779], &pointers[780], &pointers[781], &pointers[782], &pointers[783], &pointers[784], &pointers[785], &pointers[786], &pointers[787], &pointers[788], &pointers[789], &pointers[790], &pointers[791], &pointers[792], &pointers[793], &pointers[794], &pointers[795], &pointers[796], &pointers[797], &pointers[798], &pointers[799], &pointers[800],
  &pointers[801], &pointers[802], &pointers[803], &pointers[804], &pointers[805], &pointers[806], &pointers[807], &pointers[808], &pointers[809], &pointers[810], &pointers[811], &pointers[812], &pointers[813], &pointers[814], &pointers[815], &pointers[816], &pointers[817], &pointers[818], &pointers[819], &pointers[820], &pointers[821], &pointers[822], &pointers[823], &pointers[824], &pointers[825], &pointers[826], &pointers[827], &pointers[828], &pointers[829], &pointers[830], &pointers[831], &pointers[832], &pointers[833], &pointers[834], &pointers[835], &pointers[836], &pointers[837], &pointers[838], &pointers[839], &pointers[840], &pointers[841], &pointers[842], &pointers[843], &pointers[844], &pointers[845], &pointers[846], &pointers[847], &pointers[848], &pointers[849], &pointers[850],
  &pointers[851], &pointers[852], &pointers[853], &pointers[854], &pointers[855], &pointers[856], &pointers[857], &pointers[858], &pointers[859], &pointers[860], &pointers[861], &pointers[862], &pointers[863], &pointers[864], &pointers[865], &pointers[866], &pointers[867], &pointers[868], &pointers[869], &pointers[870], &pointers[871], &pointers[872], &pointers[873], &pointers[874], &pointers[875], &pointers[876], &pointers[877], &pointers[878], &pointers[879], &pointers[880], &pointers[881], &pointers[882], &pointers[883], &pointers[884], &pointers[885], &pointers[886], &pointers[887], &pointers[888], &pointers[889], &pointers[890], &pointers[891], &pointers[892], &pointers[893], &pointers[894], &pointers[895], &pointers[896], &pointers[897], &pointers[898], &pointers[899], &pointers[900],
  &pointers[901], &pointers[902], &pointers[903], &pointers[904], &pointers[905], &pointers[906], &pointers[907], &pointers[908], &pointers[909], &pointers[910], &pointers[911], &pointers[912], &pointers[913], &pointers[914], &pointers[915], &pointers[916], &pointers[917], &pointers[918], &pointers[919], &pointers[920], &pointers[921], &pointers[922], &pointers[923], &pointers[924], &pointers[925], &pointers[926], &pointers[927], &pointers[928], &pointers[929], &pointers[930], &pointers[931], &pointers[932], &pointers[933], &pointers[934], &pointers[935], &pointers[936], &pointers[937], &pointers[938], &pointers[939], &pointers[940], &pointers[941], &pointers[942], &pointers[943], &pointers[944], &pointers[945], &pointers[946], &pointers[947], &pointers[948], &pointers[949], &pointers[950],
  &pointers[951], &pointers[952], &pointers[953], &pointers[954], &pointers[955], &pointers[956], &pointers[957], &pointers[958], &pointers[959], &pointers[960], &pointers[961], &pointers[962], &pointers[963], &pointers[964], &pointers[965], &pointers[966], &pointers[967], &pointers[968], &pointers[969], &pointers[970], &pointers[971], &pointers[972], &pointers[973], &pointers[974], &pointers[975], &pointers[976], &pointers[977], &pointers[978], &pointers[979], &pointers[980], &pointers[981], &pointers[982], &pointers[983], &pointers[984], &pointers[985], &pointers[986], &pointers[987], &pointers[988], &pointers[989], &pointers[990], &pointers[991], &pointers[992], &pointers[993], &pointers[994], &pointers[995], &pointers[996], &pointers[997], &pointers[998], &pointers[999], NULL };

#endif

#ifdef POINTER_SIZE_1250
#ifdef FUNCTIONS_DATA_ON_CCM
  __attribute__((section(".ccmramdata")))
#endif
#ifdef FUNCTIONS_DATA_ON_FLASH
  const
#endif
   void *
#ifdef FUNCTIONS_DATA_ON_FLASH
  const
#endif
  pointers[1250] = {
  &pointers[1], &pointers[2], &pointers[3], &pointers[4], &pointers[5], &pointers[6], &pointers[7], &pointers[8], &pointers[9], &pointers[10], &pointers[11], &pointers[12], &pointers[13], &pointers[14], &pointers[15], &pointers[16], &pointers[17], &pointers[18], &pointers[19], &pointers[20], &pointers[21], &pointers[22], &pointers[23], &pointers[24], &pointers[25], &pointers[26], &pointers[27], &pointers[28], &pointers[29], &pointers[30], &pointers[31], &pointers[32], &pointers[33], &pointers[34], &pointers[35], &pointers[36], &pointers[37], &pointers[38], &pointers[39], &pointers[40], &pointers[41], &pointers[42], &pointers[43], &pointers[44], &pointers[45], &pointers[46], &pointers[47], &pointers[48], &pointers[49], &pointers[50],
  &pointers[51], &pointers[52], &pointers[53], &pointers[54], &pointers[55], &pointers[56], &pointers[57], &pointers[58], &pointers[59], &pointers[60], &pointers[61], &pointers[62], &pointers[63], &pointers[64], &pointers[65], &pointers[66], &pointers[67], &pointers[68], &pointers[69], &pointers[70], &pointers[71], &pointers[72], &pointers[73], &pointers[74], &pointers[75], &pointers[76], &pointers[77], &pointers[78], &pointers[79], &pointers[80], &pointers[81], &pointers[82], &pointers[83], &pointers[84], &pointers[85], &pointers[86], &pointers[87], &pointers[88], &pointers[89], &pointers[90], &pointers[91], &pointers[92], &pointers[93], &pointers[94], &pointers[95], &pointers[96], &pointers[97], &pointers[98], &pointers[99], &pointers[100],
  &pointers[101], &pointers[102], &pointers[103], &pointers[104], &pointers[105], &pointers[106], &pointers[107], &pointers[108], &pointers[109], &pointers[110], &pointers[111], &pointers[112], &pointers[113], &pointers[114], &pointers[115], &pointers[116], &pointers[117], &pointers[118], &pointers[119], &pointers[120], &pointers[121], &pointers[122], &pointers[123], &pointers[124], &pointers[125], &pointers[126], &pointers[127], &pointers[128], &pointers[129], &pointers[130], &pointers[131], &pointers[132], &pointers[133], &pointers[134], &pointers[135], &pointers[136], &pointers[137], &pointers[138], &pointers[139], &pointers[140], &pointers[141], &pointers[142], &pointers[143], &pointers[144], &pointers[145], &pointers[146], &pointers[147], &pointers[148], &pointers[149], &pointers[150],
  &pointers[151], &pointers[152], &pointers[153], &pointers[154], &pointers[155], &pointers[156], &pointers[157], &pointers[158], &pointers[159], &pointers[160], &pointers[161], &pointers[162], &pointers[163], &pointers[164], &pointers[165], &pointers[166], &pointers[167], &pointers[168], &pointers[169], &pointers[170], &pointers[171], &pointers[172], &pointers[173], &pointers[174], &pointers[175], &pointers[176], &pointers[177], &pointers[178], &pointers[179], &pointers[180], &pointers[181], &pointers[182], &pointers[183], &pointers[184], &pointers[185], &pointers[186], &pointers[187], &pointers[188], &pointers[189], &pointers[190], &pointers[191], &pointers[192], &pointers[193], &pointers[194], &pointers[195], &pointers[196], &pointers[197], &pointers[198], &pointers[199], &pointers[200],
  &pointers[201], &pointers[202], &pointers[203], &pointers[204], &pointers[205], &pointers[206], &pointers[207], &pointers[208], &pointers[209], &pointers[210], &pointers[211], &pointers[212], &pointers[213], &pointers[214], &pointers[215], &pointers[216], &pointers[217], &pointers[218], &pointers[219], &pointers[220], &pointers[221], &pointers[222], &pointers[223], &pointers[224], &pointers[225], &pointers[226], &pointers[227], &pointers[228], &pointers[229], &pointers[230], &pointers[231], &pointers[232], &pointers[233], &pointers[234], &pointers[235], &pointers[236], &pointers[237], &pointers[238], &pointers[239], &pointers[240], &pointers[241], &pointers[242], &pointers[243], &pointers[244], &pointers[245], &pointers[246], &pointers[247], &pointers[248], &pointers[249], &pointers[250],
  &pointers[251], &pointers[252], &pointers[253], &pointers[254], &pointers[255], &pointers[256], &pointers[257], &pointers[258], &pointers[259], &pointers[260], &pointers[261], &pointers[262], &pointers[263], &pointers[264], &pointers[265], &pointers[266], &pointers[267], &pointers[268], &pointers[269], &pointers[270], &pointers[271], &pointers[272], &pointers[273], &pointers[274], &pointers[275], &pointers[276], &pointers[277], &pointers[278], &pointers[279], &pointers[280], &pointers[281], &pointers[282], &pointers[283], &pointers[284], &pointers[285], &pointers[286], &pointers[287], &pointers[288], &pointers[289], &pointers[290], &pointers[291], &pointers[292], &pointers[293], &pointers[294], &pointers[295], &pointers[296], &pointers[297], &pointers[298], &pointers[299], &pointers[300],
  &pointers[301], &pointers[302], &pointers[303], &pointers[304], &pointers[305], &pointers[306], &pointers[307], &pointers[308], &pointers[309], &pointers[310], &pointers[311], &pointers[312], &pointers[313], &pointers[314], &pointers[315], &pointers[316], &pointers[317], &pointers[318], &pointers[319], &pointers[320], &pointers[321], &pointers[322], &pointers[323], &pointers[324], &pointers[325], &pointers[326], &pointers[327], &pointers[328], &pointers[329], &pointers[330], &pointers[331], &pointers[332], &pointers[333], &pointers[334], &pointers[335], &pointers[336], &pointers[337], &pointers[338], &pointers[339], &pointers[340], &pointers[341], &pointers[342], &pointers[343], &pointers[344], &pointers[345], &pointers[346], &pointers[347], &pointers[348], &pointers[349], &pointers[350],
  &pointers[351], &pointers[352], &pointers[353], &pointers[354], &pointers[355], &pointers[356], &pointers[357], &pointers[358], &pointers[359], &pointers[360], &pointers[361], &pointers[362], &pointers[363], &pointers[364], &pointers[365], &pointers[366], &pointers[367], &pointers[368], &pointers[369], &pointers[370], &pointers[371], &pointers[372], &pointers[373], &pointers[374], &pointers[375], &pointers[376], &pointers[377], &pointers[378], &pointers[379], &pointers[380], &pointers[381], &pointers[382], &pointers[383], &pointers[384], &pointers[385], &pointers[386], &pointers[387], &pointers[388], &pointers[389], &pointers[390], &pointers[391], &pointers[392], &pointers[393], &pointers[394], &pointers[395], &pointers[396], &pointers[397], &pointers[398], &pointers[399], &pointers[400],
  &pointers[401], &pointers[402], &pointers[403], &pointers[404], &pointers[405], &pointers[406], &pointers[407], &pointers[408], &pointers[409], &pointers[410], &pointers[411], &pointers[412], &pointers[413], &pointers[414], &pointers[415], &pointers[416], &pointers[417], &pointers[418], &pointers[419], &pointers[420], &pointers[421], &pointers[422], &pointers[423], &pointers[424], &pointers[425], &pointers[426], &pointers[427], &pointers[428], &pointers[429], &pointers[430], &pointers[431], &pointers[432], &pointers[433], &pointers[434], &pointers[435], &pointers[436], &pointers[437], &pointers[438], &pointers[439], &pointers[440], &pointers[441], &pointers[442], &pointers[443], &pointers[444], &pointers[445], &pointers[446], &pointers[447], &pointers[448], &pointers[449], &pointers[450],
  &pointers[451], &pointers[452], &pointers[453], &pointers[454], &pointers[455], &pointers[456], &pointers[457], &pointers[458], &pointers[459], &pointers[460], &pointers[461], &pointers[462], &pointers[463], &pointers[464], &pointers[465], &pointers[466], &pointers[467], &pointers[468], &pointers[469], &pointers[470], &pointers[471], &pointers[472], &pointers[473], &pointers[474], &pointers[475], &pointers[476], &pointers[477], &pointers[478], &pointers[479], &pointers[480], &pointers[481], &pointers[482], &pointers[483], &pointers[484], &pointers[485], &pointers[486], &pointers[487], &pointers[488], &pointers[489], &pointers[490], &pointers[491], &pointers[492], &pointers[493], &pointers[494], &pointers[495], &pointers[496], &pointers[497], &pointers[498], &pointers[499], &pointers[500],
  &pointers[501], &pointers[502], &pointers[503], &pointers[504], &pointers[505], &pointers[506], &pointers[507], &pointers[508], &pointers[509], &pointers[510], &pointers[511], &pointers[512], &pointers[513], &pointers[514], &pointers[515], &pointers[516], &pointers[517], &pointers[518], &pointers[519], &pointers[520], &pointers[521], &pointers[522], &pointers[523], &pointers[524], &pointers[525], &pointers[526], &pointers[527], &pointers[528], &pointers[529], &pointers[530], &pointers[531], &pointers[532], &pointers[533], &pointers[534], &pointers[535], &pointers[536], &pointers[537], &pointers[538], &pointers[539], &pointers[540], &pointers[541], &pointers[542], &pointers[543], &pointers[544], &pointers[545], &pointers[546], &pointers[547], &pointers[548], &pointers[549], &pointers[550],
  &pointers[551], &pointers[552], &pointers[553], &pointers[554], &pointers[555], &pointers[556], &pointers[557], &pointers[558], &pointers[559], &pointers[560], &pointers[561], &pointers[562], &pointers[563], &pointers[564], &pointers[565], &pointers[566], &pointers[567], &pointers[568], &pointers[569], &pointers[570], &pointers[571], &pointers[572], &pointers[573], &pointers[574], &pointers[575], &pointers[576], &pointers[577], &pointers[578], &pointers[579], &pointers[580], &pointers[581], &pointers[582], &pointers[583], &pointers[584], &pointers[585], &pointers[586], &pointers[587], &pointers[588], &pointers[589], &pointers[590], &pointers[591], &pointers[592], &pointers[593], &pointers[594], &pointers[595], &pointers[596], &pointers[597], &pointers[598], &pointers[599], &pointers[600],
  &pointers[601], &pointers[602], &pointers[603], &pointers[604], &pointers[605], &pointers[606], &pointers[607], &pointers[608], &pointers[609], &pointers[610], &pointers[611], &pointers[612], &pointers[613], &pointers[614], &pointers[615], &pointers[616], &pointers[617], &pointers[618], &pointers[619], &pointers[620], &pointers[621], &pointers[622], &pointers[623], &pointers[624], &pointers[625], &pointers[626], &pointers[627], &pointers[628], &pointers[629], &pointers[630], &pointers[631], &pointers[632], &pointers[633], &pointers[634], &pointers[635], &pointers[636], &pointers[637], &pointers[638], &pointers[639], &pointers[640], &pointers[641], &pointers[642], &pointers[643], &pointers[644], &pointers[645], &pointers[646], &pointers[647], &pointers[648], &pointers[649], &pointers[650],
  &pointers[651], &pointers[652], &pointers[653], &pointers[654], &pointers[655], &pointers[656], &pointers[657], &pointers[658], &pointers[659], &pointers[660], &pointers[661], &pointers[662], &pointers[663], &pointers[664], &pointers[665], &pointers[666], &pointers[667], &pointers[668], &pointers[669], &pointers[670], &pointers[671], &pointers[672], &pointers[673], &pointers[674], &pointers[675], &pointers[676], &pointers[677], &pointers[678], &pointers[679], &pointers[680], &pointers[681], &pointers[682], &pointers[683], &pointers[684], &pointers[685], &pointers[686], &pointers[687], &pointers[688], &pointers[689], &pointers[690], &pointers[691], &pointers[692], &pointers[693], &pointers[694], &pointers[695], &pointers[696], &pointers[697], &pointers[698], &pointers[699], &pointers[700],
  &pointers[701], &pointers[702], &pointers[703], &pointers[704], &pointers[705], &pointers[706], &pointers[707], &pointers[708], &pointers[709], &pointers[710], &pointers[711], &pointers[712], &pointers[713], &pointers[714], &pointers[715], &pointers[716], &pointers[717], &pointers[718], &pointers[719], &pointers[720], &pointers[721], &pointers[722], &pointers[723], &pointers[724], &pointers[725], &pointers[726], &pointers[727], &pointers[728], &pointers[729], &pointers[730], &pointers[731], &pointers[732], &pointers[733], &pointers[734], &pointers[735], &pointers[736], &pointers[737], &pointers[738], &pointers[739], &pointers[740], &pointers[741], &pointers[742], &pointers[743], &pointers[744], &pointers[745], &pointers[746], &pointers[747], &pointers[748], &pointers[749], &pointers[750],
  &pointers[751], &pointers[752], &pointers[753], &pointers[754], &pointers[755], &pointers[756], &pointers[757], &pointers[758], &pointers[759], &pointers[760], &pointers[761], &pointers[762], &pointers[763], &pointers[764], &pointers[765], &pointers[766], &pointers[767], &pointers[768], &pointers[769], &pointers[770], &pointers[771], &pointers[772], &pointers[773], &pointers[774], &pointers[775], &pointers[776], &pointers[777], &pointers[778], &pointers[779], &pointers[780], &pointers[781], &pointers[782], &pointers[783], &pointers[784], &pointers[785], &pointers[786], &pointers[787], &pointers[788], &pointers[789], &pointers[790], &pointers[791], &pointers[792], &pointers[793], &pointers[794], &pointers[795], &pointers[796], &pointers[797], &pointers[798], &pointers[799], &pointers[800],
  &pointers[801], &pointers[802], &pointers[803], &pointers[804], &pointers[805], &pointers[806], &pointers[807], &pointers[808], &pointers[809], &pointers[810], &pointers[811], &pointers[812], &pointers[813], &pointers[814], &pointers[815], &pointers[816], &pointers[817], &pointers[818], &pointers[819], &pointers[820], &pointers[821], &pointers[822], &pointers[823], &pointers[824], &pointers[825], &pointers[826], &pointers[827], &pointers[828], &pointers[829], &pointers[830], &pointers[831], &pointers[832], &pointers[833], &pointers[834], &pointers[835], &pointers[836], &pointers[837], &pointers[838], &pointers[839], &pointers[840], &pointers[841], &pointers[842], &pointers[843], &pointers[844], &pointers[845], &pointers[846], &pointers[847], &pointers[848], &pointers[849], &pointers[850],
  &pointers[851], &pointers[852], &pointers[853], &pointers[854], &pointers[855], &pointers[856], &pointers[857], &pointers[858], &pointers[859], &pointers[860], &pointers[861], &pointers[862], &pointers[863], &pointers[864], &pointers[865], &pointers[866], &pointers[867], &pointers[868], &pointers[869], &pointers[870], &pointers[871], &pointers[872], &pointers[873], &pointers[874], &pointers[875], &pointers[876], &pointers[877], &pointers[878], &pointers[879], &pointers[880], &pointers[881], &pointers[882], &pointers[883], &pointers[884], &pointers[885], &pointers[886], &pointers[887], &pointers[888], &pointers[889], &pointers[890], &pointers[891], &pointers[892], &pointers[893], &pointers[894], &pointers[895], &pointers[896], &pointers[897], &pointers[898], &pointers[899], &pointers[900],
  &pointers[901], &pointers[902], &pointers[903], &pointers[904], &pointers[905], &pointers[906], &pointers[907], &pointers[908], &pointers[909], &pointers[910], &pointers[911], &pointers[912], &pointers[913], &pointers[914], &pointers[915], &pointers[916], &pointers[917], &pointers[918], &pointers[919], &pointers[920], &pointers[921], &pointers[922], &pointers[923], &pointers[924], &pointers[925], &pointers[926], &pointers[927], &pointers[928], &pointers[929], &pointers[930], &pointers[931], &pointers[932], &pointers[933], &pointers[934], &pointers[935], &pointers[936], &pointers[937], &pointers[938], &pointers[939], &pointers[940], &pointers[941], &pointers[942], &pointers[943], &pointers[944], &pointers[945], &pointers[946], &pointers[947], &pointers[948], &pointers[949], &pointers[950],
  &pointers[951], &pointers[952], &pointers[953], &pointers[954], &pointers[955], &pointers[956], &pointers[957], &pointers[958], &pointers[959], &pointers[960], &pointers[961], &pointers[962], &pointers[963], &pointers[964], &pointers[965], &pointers[966], &pointers[967], &pointers[968], &pointers[969], &pointers[970], &pointers[971], &pointers[972], &pointers[973], &pointers[974], &pointers[975], &pointers[976], &pointers[977], &pointers[978], &pointers[979], &pointers[980], &pointers[981], &pointers[982], &pointers[983], &pointers[984], &pointers[985], &pointers[986], &pointers[987], &pointers[988], &pointers[989], &pointers[990], &pointers[991], &pointers[992], &pointers[993], &pointers[994], &pointers[995], &pointers[996], &pointers[997], &pointers[998], &pointers[999], &pointers[1000],
  &pointers[1001], &pointers[1002], &pointers[1003], &pointers[1004], &pointers[1005], &pointers[1006], &pointers[1007], &pointers[1008], &pointers[1009], &pointers[1010], &pointers[1011], &pointers[1012], &pointers[1013], &pointers[1014], &pointers[1015], &pointers[1016], &pointers[1017], &pointers[1018], &pointers[1019], &pointers[1020], &pointers[1021], &pointers[1022], &pointers[1023], &pointers[1024], &pointers[1025], &pointers[1026], &pointers[1027], &pointers[1028], &pointers[1029], &pointers[1030], &pointers[1031], &pointers[1032], &pointers[1033], &pointers[1034], &pointers[1035], &pointers[1036], &pointers[1037], &pointers[1038], &pointers[1039], &pointers[1040], &pointers[1041], &pointers[1042], &pointers[1043], &pointers[1044], &pointers[1045], &pointers[1046], &pointers[1047], &pointers[1048], &pointers[1049], &pointers[1050],
  &pointers[1051], &pointers[1052], &pointers[1053], &pointers[1054], &pointers[1055], &pointers[1056], &pointers[1057], &pointers[1058], &pointers[1059], &pointers[1060], &pointers[1061], &pointers[1062], &pointers[1063], &pointers[1064], &pointers[1065], &pointers[1066], &pointers[1067], &pointers[1068], &pointers[1069], &pointers[1070], &pointers[1071], &pointers[1072], &pointers[1073], &pointers[1074], &pointers[1075], &pointers[1076], &pointers[1077], &pointers[1078], &pointers[1079], &pointers[1080], &pointers[1081], &pointers[1082], &pointers[1083], &pointers[1084], &pointers[1085], &pointers[1086], &pointers[1087], &pointers[1088], &pointers[1089], &pointers[1090], &pointers[1091], &pointers[1092], &pointers[1093], &pointers[1094], &pointers[1095], &pointers[1096], &pointers[1097], &pointers[1098], &pointers[1099], &pointers[1100],
  &pointers[1101], &pointers[1102], &pointers[1103], &pointers[1104], &pointers[1105], &pointers[1106], &pointers[1107], &pointers[1108], &pointers[1109], &pointers[1110], &pointers[1111], &pointers[1112], &pointers[1113], &pointers[1114], &pointers[1115], &pointers[1116], &pointers[1117], &pointers[1118], &pointers[1119], &pointers[1120], &pointers[1121], &pointers[1122], &pointers[1123], &pointers[1124], &pointers[1125], &pointers[1126], &pointers[1127], &pointers[1128], &pointers[1129], &pointers[1130], &pointers[1131], &pointers[1132], &pointers[1133], &pointers[1134], &pointers[1135], &pointers[1136], &pointers[1137], &pointers[1138], &pointers[1139], &pointers[1140], &pointers[1141], &pointers[1142], &pointers[1143], &pointers[1144], &pointers[1145], &pointers[1146], &pointers[1147], &pointers[1148], &pointers[1149], &pointers[1150],
  &pointers[1151], &pointers[1152], &pointers[1153], &pointers[1154], &pointers[1155], &pointers[1156], &pointers[1157], &pointers[1158], &pointers[1159], &pointers[1160], &pointers[1161], &pointers[1162], &pointers[1163], &pointers[1164], &pointers[1165], &pointers[1166], &pointers[1167], &pointers[1168], &pointers[1169], &pointers[1170], &pointers[1171], &pointers[1172], &pointers[1173], &pointers[1174], &pointers[1175], &pointers[1176], &pointers[1177], &pointers[1178], &pointers[1179], &pointers[1180], &pointers[1181], &pointers[1182], &pointers[1183], &pointers[1184], &pointers[1185], &pointers[1186], &pointers[1187], &pointers[1188], &pointers[1189], &pointers[1190], &pointers[1191], &pointers[1192], &pointers[1193], &pointers[1194], &pointers[1195], &pointers[1196], &pointers[1197], &pointers[1198], &pointers[1199], &pointers[1200],
  &pointers[1201], &pointers[1202], &pointers[1203], &pointers[1204], &pointers[1205], &pointers[1206], &pointers[1207], &pointers[1208], &pointers[1209], &pointers[1210], &pointers[1211], &pointers[1212], &pointers[1213], &pointers[1214], &pointers[1215], &pointers[1216], &pointers[1217], &pointers[1218], &pointers[1219], &pointers[1220], &pointers[1221], &pointers[1222], &pointers[1223], &pointers[1224], &pointers[1225], &pointers[1226], &pointers[1227], &pointers[1228], &pointers[1229], &pointers[1230], &pointers[1231], &pointers[1232], &pointers[1233], &pointers[1234], &pointers[1235], &pointers[1236], &pointers[1237], &pointers[1238], &pointers[1239], &pointers[1240], &pointers[1241], &pointers[1242], &pointers[1243], &pointers[1244], &pointers[1245], &pointers[1246], &pointers[1247], &pointers[1248], &pointers[1249], NULL };
#endif

#ifdef POINTER_SIZE_1500
#ifdef FUNCTIONS_DATA_ON_CCM
  __attribute__((section(".ccmramdata")))
#endif
#ifdef FUNCTIONS_DATA_ON_FLASH
  const
#endif
   void *
#ifdef FUNCTIONS_DATA_ON_FLASH
  const
#endif
  pointers[1500] = {
  &pointers[1], &pointers[2], &pointers[3], &pointers[4], &pointers[5], &pointers[6], &pointers[7], &pointers[8], &pointers[9], &pointers[10], &pointers[11], &pointers[12], &pointers[13], &pointers[14], &pointers[15], &pointers[16], &pointers[17], &pointers[18], &pointers[19], &pointers[20], &pointers[21], &pointers[22], &pointers[23], &pointers[24], &pointers[25], &pointers[26], &pointers[27], &pointers[28], &pointers[29], &pointers[30], &pointers[31], &pointers[32], &pointers[33], &pointers[34], &pointers[35], &pointers[36], &pointers[37], &pointers[38], &pointers[39], &pointers[40], &pointers[41], &pointers[42], &pointers[43], &pointers[44], &pointers[45], &pointers[46], &pointers[47], &pointers[48], &pointers[49], &pointers[50],
  &pointers[51], &pointers[52], &pointers[53], &pointers[54], &pointers[55], &pointers[56], &pointers[57], &pointers[58], &pointers[59], &pointers[60], &pointers[61], &pointers[62], &pointers[63], &pointers[64], &pointers[65], &pointers[66], &pointers[67], &pointers[68], &pointers[69], &pointers[70], &pointers[71], &pointers[72], &pointers[73], &pointers[74], &pointers[75], &pointers[76], &pointers[77], &pointers[78], &pointers[79], &pointers[80], &pointers[81], &pointers[82], &pointers[83], &pointers[84], &pointers[85], &pointers[86], &pointers[87], &pointers[88], &pointers[89], &pointers[90], &pointers[91], &pointers[92], &pointers[93], &pointers[94], &pointers[95], &pointers[96], &pointers[97], &pointers[98], &pointers[99], &pointers[100],
  &pointers[101], &pointers[102], &pointers[103], &pointers[104], &pointers[105], &pointers[106], &pointers[107], &pointers[108], &pointers[109], &pointers[110], &pointers[111], &pointers[112], &pointers[113], &pointers[114], &pointers[115], &pointers[116], &pointers[117], &pointers[118], &pointers[119], &pointers[120], &pointers[121], &pointers[122], &pointers[123], &pointers[124], &pointers[125], &pointers[126], &pointers[127], &pointers[128], &pointers[129], &pointers[130], &pointers[131], &pointers[132], &pointers[133], &pointers[134], &pointers[135], &pointers[136], &pointers[137], &pointers[138], &pointers[139], &pointers[140], &pointers[141], &pointers[142], &pointers[143], &pointers[144], &pointers[145], &pointers[146], &pointers[147], &pointers[148], &pointers[149], &pointers[150],
  &pointers[151], &pointers[152], &pointers[153], &pointers[154], &pointers[155], &pointers[156], &pointers[157], &pointers[158], &pointers[159], &pointers[160], &pointers[161], &pointers[162], &pointers[163], &pointers[164], &pointers[165], &pointers[166], &pointers[167], &pointers[168], &pointers[169], &pointers[170], &pointers[171], &pointers[172], &pointers[173], &pointers[174], &pointers[175], &pointers[176], &pointers[177], &pointers[178], &pointers[179], &pointers[180], &pointers[181], &pointers[182], &pointers[183], &pointers[184], &pointers[185], &pointers[186], &pointers[187], &pointers[188], &pointers[189], &pointers[190], &pointers[191], &pointers[192], &pointers[193], &pointers[194], &pointers[195], &pointers[196], &pointers[197], &pointers[198], &pointers[199], &pointers[200],
  &pointers[201], &pointers[202], &pointers[203], &pointers[204], &pointers[205], &pointers[206], &pointers[207], &pointers[208], &pointers[209], &pointers[210], &pointers[211], &pointers[212], &pointers[213], &pointers[214], &pointers[215], &pointers[216], &pointers[217], &pointers[218], &pointers[219], &pointers[220], &pointers[221], &pointers[222], &pointers[223], &pointers[224], &pointers[225], &pointers[226], &pointers[227], &pointers[228], &pointers[229], &pointers[230], &pointers[231], &pointers[232], &pointers[233], &pointers[234], &pointers[235], &pointers[236], &pointers[237], &pointers[238], &pointers[239], &pointers[240], &pointers[241], &pointers[242], &pointers[243], &pointers[244], &pointers[245], &pointers[246], &pointers[247], &pointers[248], &pointers[249], &pointers[250],
  &pointers[251], &pointers[252], &pointers[253], &pointers[254], &pointers[255], &pointers[256], &pointers[257], &pointers[258], &pointers[259], &pointers[260], &pointers[261], &pointers[262], &pointers[263], &pointers[264], &pointers[265], &pointers[266], &pointers[267], &pointers[268], &pointers[269], &pointers[270], &pointers[271], &pointers[272], &pointers[273], &pointers[274], &pointers[275], &pointers[276], &pointers[277], &pointers[278], &pointers[279], &pointers[280], &pointers[281], &pointers[282], &pointers[283], &pointers[284], &pointers[285], &pointers[286], &pointers[287], &pointers[288], &pointers[289], &pointers[290], &pointers[291], &pointers[292], &pointers[293], &pointers[294], &pointers[295], &pointers[296], &pointers[297], &pointers[298], &pointers[299], &pointers[300],
  &pointers[301], &pointers[302], &pointers[303], &pointers[304], &pointers[305], &pointers[306], &pointers[307], &pointers[308], &pointers[309], &pointers[310], &pointers[311], &pointers[312], &pointers[313], &pointers[314], &pointers[315], &pointers[316], &pointers[317], &pointers[318], &pointers[319], &pointers[320], &pointers[321], &pointers[322], &pointers[323], &pointers[324], &pointers[325], &pointers[326], &pointers[327], &pointers[328], &pointers[329], &pointers[330], &pointers[331], &pointers[332], &pointers[333], &pointers[334], &pointers[335], &pointers[336], &pointers[337], &pointers[338], &pointers[339], &pointers[340], &pointers[341], &pointers[342], &pointers[343], &pointers[344], &pointers[345], &pointers[346], &pointers[347], &pointers[348], &pointers[349], &pointers[350],
  &pointers[351], &pointers[352], &pointers[353], &pointers[354], &pointers[355], &pointers[356], &pointers[357], &pointers[358], &pointers[359], &pointers[360], &pointers[361], &pointers[362], &pointers[363], &pointers[364], &pointers[365], &pointers[366], &pointers[367], &pointers[368], &pointers[369], &pointers[370], &pointers[371], &pointers[372], &pointers[373], &pointers[374], &pointers[375], &pointers[376], &pointers[377], &pointers[378], &pointers[379], &pointers[380], &pointers[381], &pointers[382], &pointers[383], &pointers[384], &pointers[385], &pointers[386], &pointers[387], &pointers[388], &pointers[389], &pointers[390], &pointers[391], &pointers[392], &pointers[393], &pointers[394], &pointers[395], &pointers[396], &pointers[397], &pointers[398], &pointers[399], &pointers[400],
  &pointers[401], &pointers[402], &pointers[403], &pointers[404], &pointers[405], &pointers[406], &pointers[407], &pointers[408], &pointers[409], &pointers[410], &pointers[411], &pointers[412], &pointers[413], &pointers[414], &pointers[415], &pointers[416], &pointers[417], &pointers[418], &pointers[419], &pointers[420], &pointers[421], &pointers[422], &pointers[423], &pointers[424], &pointers[425], &pointers[426], &pointers[427], &pointers[428], &pointers[429], &pointers[430], &pointers[431], &pointers[432], &pointers[433], &pointers[434], &pointers[435], &pointers[436], &pointers[437], &pointers[438], &pointers[439], &pointers[440], &pointers[441], &pointers[442], &pointers[443], &pointers[444], &pointers[445], &pointers[446], &pointers[447], &pointers[448], &pointers[449], &pointers[450],
  &pointers[451], &pointers[452], &pointers[453], &pointers[454], &pointers[455], &pointers[456], &pointers[457], &pointers[458], &pointers[459], &pointers[460], &pointers[461], &pointers[462], &pointers[463], &pointers[464], &pointers[465], &pointers[466], &pointers[467], &pointers[468], &pointers[469], &pointers[470], &pointers[471], &pointers[472], &pointers[473], &pointers[474], &pointers[475], &pointers[476], &pointers[477], &pointers[478], &pointers[479], &pointers[480], &pointers[481], &pointers[482], &pointers[483], &pointers[484], &pointers[485], &pointers[486], &pointers[487], &pointers[488], &pointers[489], &pointers[490], &pointers[491], &pointers[492], &pointers[493], &pointers[494], &pointers[495], &pointers[496], &pointers[497], &pointers[498], &pointers[499], &pointers[500],
  &pointers[501], &pointers[502], &pointers[503], &pointers[504], &pointers[505], &pointers[506], &pointers[507], &pointers[508], &pointers[509], &pointers[510], &pointers[511], &pointers[512], &pointers[513], &pointers[514], &pointers[515], &pointers[516], &pointers[517], &pointers[518], &pointers[519], &pointers[520], &pointers[521], &pointers[522], &pointers[523], &pointers[524], &pointers[525], &pointers[526], &pointers[527], &pointers[528], &pointers[529], &pointers[530], &pointers[531], &pointers[532], &pointers[533], &pointers[534], &pointers[535], &pointers[536], &pointers[537], &pointers[538], &pointers[539], &pointers[540], &pointers[541], &pointers[542], &pointers[543], &pointers[544], &pointers[545], &pointers[546], &pointers[547], &pointers[548], &pointers[549], &pointers[550],
  &pointers[551], &pointers[552], &pointers[553], &pointers[554], &pointers[555], &pointers[556], &pointers[557], &pointers[558], &pointers[559], &pointers[560], &pointers[561], &pointers[562], &pointers[563], &pointers[564], &pointers[565], &pointers[566], &pointers[567], &pointers[568], &pointers[569], &pointers[570], &pointers[571], &pointers[572], &pointers[573], &pointers[574], &pointers[575], &pointers[576], &pointers[577], &pointers[578], &pointers[579], &pointers[580], &pointers[581], &pointers[582], &pointers[583], &pointers[584], &pointers[585], &pointers[586], &pointers[587], &pointers[588], &pointers[589], &pointers[590], &pointers[591], &pointers[592], &pointers[593], &pointers[594], &pointers[595], &pointers[596], &pointers[597], &pointers[598], &pointers[599], &pointers[600],
  &pointers[601], &pointers[602], &pointers[603], &pointers[604], &pointers[605], &pointers[606], &pointers[607], &pointers[608], &pointers[609], &pointers[610], &pointers[611], &pointers[612], &pointers[613], &pointers[614], &pointers[615], &pointers[616], &pointers[617], &pointers[618], &pointers[619], &pointers[620], &pointers[621], &pointers[622], &pointers[623], &pointers[624], &pointers[625], &pointers[626], &pointers[627], &pointers[628], &pointers[629], &pointers[630], &pointers[631], &pointers[632], &pointers[633], &pointers[634], &pointers[635], &pointers[636], &pointers[637], &pointers[638], &pointers[639], &pointers[640], &pointers[641], &pointers[642], &pointers[643], &pointers[644], &pointers[645], &pointers[646], &pointers[647], &pointers[648], &pointers[649], &pointers[650],
  &pointers[651], &pointers[652], &pointers[653], &pointers[654], &pointers[655], &pointers[656], &pointers[657], &pointers[658], &pointers[659], &pointers[660], &pointers[661], &pointers[662], &pointers[663], &pointers[664], &pointers[665], &pointers[666], &pointers[667], &pointers[668], &pointers[669], &pointers[670], &pointers[671], &pointers[672], &pointers[673], &pointers[674], &pointers[675], &pointers[676], &pointers[677], &pointers[678], &pointers[679], &pointers[680], &pointers[681], &pointers[682], &pointers[683], &pointers[684], &pointers[685], &pointers[686], &pointers[687], &pointers[688], &pointers[689], &pointers[690], &pointers[691], &pointers[692], &pointers[693], &pointers[694], &pointers[695], &pointers[696], &pointers[697], &pointers[698], &pointers[699], &pointers[700],
  &pointers[701], &pointers[702], &pointers[703], &pointers[704], &pointers[705], &pointers[706], &pointers[707], &pointers[708], &pointers[709], &pointers[710], &pointers[711], &pointers[712], &pointers[713], &pointers[714], &pointers[715], &pointers[716], &pointers[717], &pointers[718], &pointers[719], &pointers[720], &pointers[721], &pointers[722], &pointers[723], &pointers[724], &pointers[725], &pointers[726], &pointers[727], &pointers[728], &pointers[729], &pointers[730], &pointers[731], &pointers[732], &pointers[733], &pointers[734], &pointers[735], &pointers[736], &pointers[737], &pointers[738], &pointers[739], &pointers[740], &pointers[741], &pointers[742], &pointers[743], &pointers[744], &pointers[745], &pointers[746], &pointers[747], &pointers[748], &pointers[749], &pointers[750],
  &pointers[751], &pointers[752], &pointers[753], &pointers[754], &pointers[755], &pointers[756], &pointers[757], &pointers[758], &pointers[759], &pointers[760], &pointers[761], &pointers[762], &pointers[763], &pointers[764], &pointers[765], &pointers[766], &pointers[767], &pointers[768], &pointers[769], &pointers[770], &pointers[771], &pointers[772], &pointers[773], &pointers[774], &pointers[775], &pointers[776], &pointers[777], &pointers[778], &pointers[779], &pointers[780], &pointers[781], &pointers[782], &pointers[783], &pointers[784], &pointers[785], &pointers[786], &pointers[787], &pointers[788], &pointers[789], &pointers[790], &pointers[791], &pointers[792], &pointers[793], &pointers[794], &pointers[795], &pointers[796], &pointers[797], &pointers[798], &pointers[799], &pointers[800],
  &pointers[801], &pointers[802], &pointers[803], &pointers[804], &pointers[805], &pointers[806], &pointers[807], &pointers[808], &pointers[809], &pointers[810], &pointers[811], &pointers[812], &pointers[813], &pointers[814], &pointers[815], &pointers[816], &pointers[817], &pointers[818], &pointers[819], &pointers[820], &pointers[821], &pointers[822], &pointers[823], &pointers[824], &pointers[825], &pointers[826], &pointers[827], &pointers[828], &pointers[829], &pointers[830], &pointers[831], &pointers[832], &pointers[833], &pointers[834], &pointers[835], &pointers[836], &pointers[837], &pointers[838], &pointers[839], &pointers[840], &pointers[841], &pointers[842], &pointers[843], &pointers[844], &pointers[845], &pointers[846], &pointers[847], &pointers[848], &pointers[849], &pointers[850],
  &pointers[851], &pointers[852], &pointers[853], &pointers[854], &pointers[855], &pointers[856], &pointers[857], &pointers[858], &pointers[859], &pointers[860], &pointers[861], &pointers[862], &pointers[863], &pointers[864], &pointers[865], &pointers[866], &pointers[867], &pointers[868], &pointers[869], &pointers[870], &pointers[871], &pointers[872], &pointers[873], &pointers[874], &pointers[875], &pointers[876], &pointers[877], &pointers[878], &pointers[879], &pointers[880], &pointers[881], &pointers[882], &pointers[883], &pointers[884], &pointers[885], &pointers[886], &pointers[887], &pointers[888], &pointers[889], &pointers[890], &pointers[891], &pointers[892], &pointers[893], &pointers[894], &pointers[895], &pointers[896], &pointers[897], &pointers[898], &pointers[899], &pointers[900],
  &pointers[901], &pointers[902], &pointers[903], &pointers[904], &pointers[905], &pointers[906], &pointers[907], &pointers[908], &pointers[909], &pointers[910], &pointers[911], &pointers[912], &pointers[913], &pointers[914], &pointers[915], &pointers[916], &pointers[917], &pointers[918], &pointers[919], &pointers[920], &pointers[921], &pointers[922], &pointers[923], &pointers[924], &pointers[925], &pointers[926], &pointers[927], &pointers[928], &pointers[929], &pointers[930], &pointers[931], &pointers[932], &pointers[933], &pointers[934], &pointers[935], &pointers[936], &pointers[937], &pointers[938], &pointers[939], &pointers[940], &pointers[941], &pointers[942], &pointers[943], &pointers[944], &pointers[945], &pointers[946], &pointers[947], &pointers[948], &pointers[949], &pointers[950],
  &pointers[951], &pointers[952], &pointers[953], &pointers[954], &pointers[955], &pointers[956], &pointers[957], &pointers[958], &pointers[959], &pointers[960], &pointers[961], &pointers[962], &pointers[963], &pointers[964], &pointers[965], &pointers[966], &pointers[967], &pointers[968], &pointers[969], &pointers[970], &pointers[971], &pointers[972], &pointers[973], &pointers[974], &pointers[975], &pointers[976], &pointers[977], &pointers[978], &pointers[979], &pointers[980], &pointers[981], &pointers[982], &pointers[983], &pointers[984], &pointers[985], &pointers[986], &pointers[987], &pointers[988], &pointers[989], &pointers[990], &pointers[991], &pointers[992], &pointers[993], &pointers[994], &pointers[995], &pointers[996], &pointers[997], &pointers[998], &pointers[999], &pointers[1000],
  &pointers[1001], &pointers[1002], &pointers[1003], &pointers[1004], &pointers[1005], &pointers[1006], &pointers[1007], &pointers[1008], &pointers[1009], &pointers[1010], &pointers[1011], &pointers[1012], &pointers[1013], &pointers[1014], &pointers[1015], &pointers[1016], &pointers[1017], &pointers[1018], &pointers[1019], &pointers[1020], &pointers[1021], &pointers[1022], &pointers[1023], &pointers[1024], &pointers[1025], &pointers[1026], &pointers[1027], &pointers[1028], &pointers[1029], &pointers[1030], &pointers[1031], &pointers[1032], &pointers[1033], &pointers[1034], &pointers[1035], &pointers[1036], &pointers[1037], &pointers[1038], &pointers[1039], &pointers[1040], &pointers[1041], &pointers[1042], &pointers[1043], &pointers[1044], &pointers[1045], &pointers[1046], &pointers[1047], &pointers[1048], &pointers[1049], &pointers[1050],
  &pointers[1051], &pointers[1052], &pointers[1053], &pointers[1054], &pointers[1055], &pointers[1056], &pointers[1057], &pointers[1058], &pointers[1059], &pointers[1060], &pointers[1061], &pointers[1062], &pointers[1063], &pointers[1064], &pointers[1065], &pointers[1066], &pointers[1067], &pointers[1068], &pointers[1069], &pointers[1070], &pointers[1071], &pointers[1072], &pointers[1073], &pointers[1074], &pointers[1075], &pointers[1076], &pointers[1077], &pointers[1078], &pointers[1079], &pointers[1080], &pointers[1081], &pointers[1082], &pointers[1083], &pointers[1084], &pointers[1085], &pointers[1086], &pointers[1087], &pointers[1088], &pointers[1089], &pointers[1090], &pointers[1091], &pointers[1092], &pointers[1093], &pointers[1094], &pointers[1095], &pointers[1096], &pointers[1097], &pointers[1098], &pointers[1099], &pointers[1100],
  &pointers[1101], &pointers[1102], &pointers[1103], &pointers[1104], &pointers[1105], &pointers[1106], &pointers[1107], &pointers[1108], &pointers[1109], &pointers[1110], &pointers[1111], &pointers[1112], &pointers[1113], &pointers[1114], &pointers[1115], &pointers[1116], &pointers[1117], &pointers[1118], &pointers[1119], &pointers[1120], &pointers[1121], &pointers[1122], &pointers[1123], &pointers[1124], &pointers[1125], &pointers[1126], &pointers[1127], &pointers[1128], &pointers[1129], &pointers[1130], &pointers[1131], &pointers[1132], &pointers[1133], &pointers[1134], &pointers[1135], &pointers[1136], &pointers[1137], &pointers[1138], &pointers[1139], &pointers[1140], &pointers[1141], &pointers[1142], &pointers[1143], &pointers[1144], &pointers[1145], &pointers[1146], &pointers[1147], &pointers[1148], &pointers[1149], &pointers[1150],
  &pointers[1151], &pointers[1152], &pointers[1153], &pointers[1154], &pointers[1155], &pointers[1156], &pointers[1157], &pointers[1158], &pointers[1159], &pointers[1160], &pointers[1161], &pointers[1162], &pointers[1163], &pointers[1164], &pointers[1165], &pointers[1166], &pointers[1167], &pointers[1168], &pointers[1169], &pointers[1170], &pointers[1171], &pointers[1172], &pointers[1173], &pointers[1174], &pointers[1175], &pointers[1176], &pointers[1177], &pointers[1178], &pointers[1179], &pointers[1180], &pointers[1181], &pointers[1182], &pointers[1183], &pointers[1184], &pointers[1185], &pointers[1186], &pointers[1187], &pointers[1188], &pointers[1189], &pointers[1190], &pointers[1191], &pointers[1192], &pointers[1193], &pointers[1194], &pointers[1195], &pointers[1196], &pointers[1197], &pointers[1198], &pointers[1199], &pointers[1200],
  &pointers[1201], &pointers[1202], &pointers[1203], &pointers[1204], &pointers[1205], &pointers[1206], &pointers[1207], &pointers[1208], &pointers[1209], &pointers[1210], &pointers[1211], &pointers[1212], &pointers[1213], &pointers[1214], &pointers[1215], &pointers[1216], &pointers[1217], &pointers[1218], &pointers[1219], &pointers[1220], &pointers[1221], &pointers[1222], &pointers[1223], &pointers[1224], &pointers[1225], &pointers[1226], &pointers[1227], &pointers[1228], &pointers[1229], &pointers[1230], &pointers[1231], &pointers[1232], &pointers[1233], &pointers[1234], &pointers[1235], &pointers[1236], &pointers[1237], &pointers[1238], &pointers[1239], &pointers[1240], &pointers[1241], &pointers[1242], &pointers[1243], &pointers[1244], &pointers[1245], &pointers[1246], &pointers[1247], &pointers[1248], &pointers[1249], &pointers[1250],
  &pointers[1251], &pointers[1252], &pointers[1253], &pointers[1254], &pointers[1255], &pointers[1256], &pointers[1257], &pointers[1258], &pointers[1259], &pointers[1260], &pointers[1261], &pointers[1262], &pointers[1263], &pointers[1264], &pointers[1265], &pointers[1266], &pointers[1267], &pointers[1268], &pointers[1269], &pointers[1270], &pointers[1271], &pointers[1272], &pointers[1273], &pointers[1274], &pointers[1275], &pointers[1276], &pointers[1277], &pointers[1278], &pointers[1279], &pointers[1280], &pointers[1281], &pointers[1282], &pointers[1283], &pointers[1284], &pointers[1285], &pointers[1286], &pointers[1287], &pointers[1288], &pointers[1289], &pointers[1290], &pointers[1291], &pointers[1292], &pointers[1293], &pointers[1294], &pointers[1295], &pointers[1296], &pointers[1297], &pointers[1298], &pointers[1299], &pointers[1300],
  &pointers[1301], &pointers[1302], &pointers[1303], &pointers[1304], &pointers[1305], &pointers[1306], &pointers[1307], &pointers[1308], &pointers[1309], &pointers[1310], &pointers[1311], &pointers[1312], &pointers[1313], &pointers[1314], &pointers[1315], &pointers[1316], &pointers[1317], &pointers[1318], &pointers[1319], &pointers[1320], &pointers[1321], &pointers[1322], &pointers[1323], &pointers[1324], &pointers[1325], &pointers[1326], &pointers[1327], &pointers[1328], &pointers[1329], &pointers[1330], &pointers[1331], &pointers[1332], &pointers[1333], &pointers[1334], &pointers[1335], &pointers[1336], &pointers[1337], &pointers[1338], &pointers[1339], &pointers[1340], &pointers[1341], &pointers[1342], &pointers[1343], &pointers[1344], &pointers[1345], &pointers[1346], &pointers[1347], &pointers[1348], &pointers[1349], &pointers[1350],
  &pointers[1351], &pointers[1352], &pointers[1353], &pointers[1354], &pointers[1355], &pointers[1356], &pointers[1357], &pointers[1358], &pointers[1359], &pointers[1360], &pointers[1361], &pointers[1362], &pointers[1363], &pointers[1364], &pointers[1365], &pointers[1366], &pointers[1367], &pointers[1368], &pointers[1369], &pointers[1370], &pointers[1371], &pointers[1372], &pointers[1373], &pointers[1374], &pointers[1375], &pointers[1376], &pointers[1377], &pointers[1378], &pointers[1379], &pointers[1380], &pointers[1381], &pointers[1382], &pointers[1383], &pointers[1384], &pointers[1385], &pointers[1386], &pointers[1387], &pointers[1388], &pointers[1389], &pointers[1390], &pointers[1391], &pointers[1392], &pointers[1393], &pointers[1394], &pointers[1395], &pointers[1396], &pointers[1397], &pointers[1398], &pointers[1399], &pointers[1400],
  &pointers[1401], &pointers[1402], &pointers[1403], &pointers[1404], &pointers[1405], &pointers[1406], &pointers[1407], &pointers[1408], &pointers[1409], &pointers[1410], &pointers[1411], &pointers[1412], &pointers[1413], &pointers[1414], &pointers[1415], &pointers[1416], &pointers[1417], &pointers[1418], &pointers[1419], &pointers[1420], &pointers[1421], &pointers[1422], &pointers[1423], &pointers[1424], &pointers[1425], &pointers[1426], &pointers[1427], &pointers[1428], &pointers[1429], &pointers[1430], &pointers[1431], &pointers[1432], &pointers[1433], &pointers[1434], &pointers[1435], &pointers[1436], &pointers[1437], &pointers[1438], &pointers[1439], &pointers[1440], &pointers[1441], &pointers[1442], &pointers[1443], &pointers[1444], &pointers[1445], &pointers[1446], &pointers[1447], &pointers[1448], &pointers[1449], &pointers[1450],
  &pointers[1451], &pointers[1452], &pointers[1453], &pointers[1454], &pointers[1455], &pointers[1456], &pointers[1457], &pointers[1458], &pointers[1459], &pointers[1460], &pointers[1461], &pointers[1462], &pointers[1463], &pointers[1464], &pointers[1465], &pointers[1466], &pointers[1467], &pointers[1468], &pointers[1469], &pointers[1470], &pointers[1471], &pointers[1472], &pointers[1473], &pointers[1474], &pointers[1475], &pointers[1476], &pointers[1477], &pointers[1478], &pointers[1479], &pointers[1480], &pointers[1481], &pointers[1482], &pointers[1483], &pointers[1484], &pointers[1485], &pointers[1486], &pointers[1487], &pointers[1488], &pointers[1489], &pointers[1490], &pointers[1491], &pointers[1492], &pointers[1493], &pointers[1494], &pointers[1495], &pointers[1496], &pointers[1497], &pointers[1498], &pointers[1499], NULL };
#endif

#ifdef POINTER_SIZE_1750
#ifdef FUNCTIONS_DATA_ON_CCM
  __attribute__((section(".ccmramdata")))
#endif
#ifdef FUNCTIONS_DATA_ON_FLASH
  const
#endif
   void *
#ifdef FUNCTIONS_DATA_ON_FLASH
  const
#endif
  pointers[1750] = {
  &pointers[1], &pointers[2], &pointers[3], &pointers[4], &pointers[5], &pointers[6], &pointers[7], &pointers[8], &pointers[9], &pointers[10], &pointers[11], &pointers[12], &pointers[13], &pointers[14], &pointers[15], &pointers[16], &pointers[17], &pointers[18], &pointers[19], &pointers[20], &pointers[21], &pointers[22], &pointers[23], &pointers[24], &pointers[25], &pointers[26], &pointers[27], &pointers[28], &pointers[29], &pointers[30], &pointers[31], &pointers[32], &pointers[33], &pointers[34], &pointers[35], &pointers[36], &pointers[37], &pointers[38], &pointers[39], &pointers[40], &pointers[41], &pointers[42], &pointers[43], &pointers[44], &pointers[45], &pointers[46], &pointers[47], &pointers[48], &pointers[49], &pointers[50],
  &pointers[51], &pointers[52], &pointers[53], &pointers[54], &pointers[55], &pointers[56], &pointers[57], &pointers[58], &pointers[59], &pointers[60], &pointers[61], &pointers[62], &pointers[63], &pointers[64], &pointers[65], &pointers[66], &pointers[67], &pointers[68], &pointers[69], &pointers[70], &pointers[71], &pointers[72], &pointers[73], &pointers[74], &pointers[75], &pointers[76], &pointers[77], &pointers[78], &pointers[79], &pointers[80], &pointers[81], &pointers[82], &pointers[83], &pointers[84], &pointers[85], &pointers[86], &pointers[87], &pointers[88], &pointers[89], &pointers[90], &pointers[91], &pointers[92], &pointers[93], &pointers[94], &pointers[95], &pointers[96], &pointers[97], &pointers[98], &pointers[99], &pointers[100],
  &pointers[101], &pointers[102], &pointers[103], &pointers[104], &pointers[105], &pointers[106], &pointers[107], &pointers[108], &pointers[109], &pointers[110], &pointers[111], &pointers[112], &pointers[113], &pointers[114], &pointers[115], &pointers[116], &pointers[117], &pointers[118], &pointers[119], &pointers[120], &pointers[121], &pointers[122], &pointers[123], &pointers[124], &pointers[125], &pointers[126], &pointers[127], &pointers[128], &pointers[129], &pointers[130], &pointers[131], &pointers[132], &pointers[133], &pointers[134], &pointers[135], &pointers[136], &pointers[137], &pointers[138], &pointers[139], &pointers[140], &pointers[141], &pointers[142], &pointers[143], &pointers[144], &pointers[145], &pointers[146], &pointers[147], &pointers[148], &pointers[149], &pointers[150],
  &pointers[151], &pointers[152], &pointers[153], &pointers[154], &pointers[155], &pointers[156], &pointers[157], &pointers[158], &pointers[159], &pointers[160], &pointers[161], &pointers[162], &pointers[163], &pointers[164], &pointers[165], &pointers[166], &pointers[167], &pointers[168], &pointers[169], &pointers[170], &pointers[171], &pointers[172], &pointers[173], &pointers[174], &pointers[175], &pointers[176], &pointers[177], &pointers[178], &pointers[179], &pointers[180], &pointers[181], &pointers[182], &pointers[183], &pointers[184], &pointers[185], &pointers[186], &pointers[187], &pointers[188], &pointers[189], &pointers[190], &pointers[191], &pointers[192], &pointers[193], &pointers[194], &pointers[195], &pointers[196], &pointers[197], &pointers[198], &pointers[199], &pointers[200],
  &pointers[201], &pointers[202], &pointers[203], &pointers[204], &pointers[205], &pointers[206], &pointers[207], &pointers[208], &pointers[209], &pointers[210], &pointers[211], &pointers[212], &pointers[213], &pointers[214], &pointers[215], &pointers[216], &pointers[217], &pointers[218], &pointers[219], &pointers[220], &pointers[221], &pointers[222], &pointers[223], &pointers[224], &pointers[225], &pointers[226], &pointers[227], &pointers[228], &pointers[229], &pointers[230], &pointers[231], &pointers[232], &pointers[233], &pointers[234], &pointers[235], &pointers[236], &pointers[237], &pointers[238], &pointers[239], &pointers[240], &pointers[241], &pointers[242], &pointers[243], &pointers[244], &pointers[245], &pointers[246], &pointers[247], &pointers[248], &pointers[249], &pointers[250],
  &pointers[251], &pointers[252], &pointers[253], &pointers[254], &pointers[255], &pointers[256], &pointers[257], &pointers[258], &pointers[259], &pointers[260], &pointers[261], &pointers[262], &pointers[263], &pointers[264], &pointers[265], &pointers[266], &pointers[267], &pointers[268], &pointers[269], &pointers[270], &pointers[271], &pointers[272], &pointers[273], &pointers[274], &pointers[275], &pointers[276], &pointers[277], &pointers[278], &pointers[279], &pointers[280], &pointers[281], &pointers[282], &pointers[283], &pointers[284], &pointers[285], &pointers[286], &pointers[287], &pointers[288], &pointers[289], &pointers[290], &pointers[291], &pointers[292], &pointers[293], &pointers[294], &pointers[295], &pointers[296], &pointers[297], &pointers[298], &pointers[299], &pointers[300],
  &pointers[301], &pointers[302], &pointers[303], &pointers[304], &pointers[305], &pointers[306], &pointers[307], &pointers[308], &pointers[309], &pointers[310], &pointers[311], &pointers[312], &pointers[313], &pointers[314], &pointers[315], &pointers[316], &pointers[317], &pointers[318], &pointers[319], &pointers[320], &pointers[321], &pointers[322], &pointers[323], &pointers[324], &pointers[325], &pointers[326], &pointers[327], &pointers[328], &pointers[329], &pointers[330], &pointers[331], &pointers[332], &pointers[333], &pointers[334], &pointers[335], &pointers[336], &pointers[337], &pointers[338], &pointers[339], &pointers[340], &pointers[341], &pointers[342], &pointers[343], &pointers[344], &pointers[345], &pointers[346], &pointers[347], &pointers[348], &pointers[349], &pointers[350],
  &pointers[351], &pointers[352], &pointers[353], &pointers[354], &pointers[355], &pointers[356], &pointers[357], &pointers[358], &pointers[359], &pointers[360], &pointers[361], &pointers[362], &pointers[363], &pointers[364], &pointers[365], &pointers[366], &pointers[367], &pointers[368], &pointers[369], &pointers[370], &pointers[371], &pointers[372], &pointers[373], &pointers[374], &pointers[375], &pointers[376], &pointers[377], &pointers[378], &pointers[379], &pointers[380], &pointers[381], &pointers[382], &pointers[383], &pointers[384], &pointers[385], &pointers[386], &pointers[387], &pointers[388], &pointers[389], &pointers[390], &pointers[391], &pointers[392], &pointers[393], &pointers[394], &pointers[395], &pointers[396], &pointers[397], &pointers[398], &pointers[399], &pointers[400],
  &pointers[401], &pointers[402], &pointers[403], &pointers[404], &pointers[405], &pointers[406], &pointers[407], &pointers[408], &pointers[409], &pointers[410], &pointers[411], &pointers[412], &pointers[413], &pointers[414], &pointers[415], &pointers[416], &pointers[417], &pointers[418], &pointers[419], &pointers[420], &pointers[421], &pointers[422], &pointers[423], &pointers[424], &pointers[425], &pointers[426], &pointers[427], &pointers[428], &pointers[429], &pointers[430], &pointers[431], &pointers[432], &pointers[433], &pointers[434], &pointers[435], &pointers[436], &pointers[437], &pointers[438], &pointers[439], &pointers[440], &pointers[441], &pointers[442], &pointers[443], &pointers[444], &pointers[445], &pointers[446], &pointers[447], &pointers[448], &pointers[449], &pointers[450],
  &pointers[451], &pointers[452], &pointers[453], &pointers[454], &pointers[455], &pointers[456], &pointers[457], &pointers[458], &pointers[459], &pointers[460], &pointers[461], &pointers[462], &pointers[463], &pointers[464], &pointers[465], &pointers[466], &pointers[467], &pointers[468], &pointers[469], &pointers[470], &pointers[471], &pointers[472], &pointers[473], &pointers[474], &pointers[475], &pointers[476], &pointers[477], &pointers[478], &pointers[479], &pointers[480], &pointers[481], &pointers[482], &pointers[483], &pointers[484], &pointers[485], &pointers[486], &pointers[487], &pointers[488], &pointers[489], &pointers[490], &pointers[491], &pointers[492], &pointers[493], &pointers[494], &pointers[495], &pointers[496], &pointers[497], &pointers[498], &pointers[499], &pointers[500],
  &pointers[501], &pointers[502], &pointers[503], &pointers[504], &pointers[505], &pointers[506], &pointers[507], &pointers[508], &pointers[509], &pointers[510], &pointers[511], &pointers[512], &pointers[513], &pointers[514], &pointers[515], &pointers[516], &pointers[517], &pointers[518], &pointers[519], &pointers[520], &pointers[521], &pointers[522], &pointers[523], &pointers[524], &pointers[525], &pointers[526], &pointers[527], &pointers[528], &pointers[529], &pointers[530], &pointers[531], &pointers[532], &pointers[533], &pointers[534], &pointers[535], &pointers[536], &pointers[537], &pointers[538], &pointers[539], &pointers[540], &pointers[541], &pointers[542], &pointers[543], &pointers[544], &pointers[545], &pointers[546], &pointers[547], &pointers[548], &pointers[549], &pointers[550],
  &pointers[551], &pointers[552], &pointers[553], &pointers[554], &pointers[555], &pointers[556], &pointers[557], &pointers[558], &pointers[559], &pointers[560], &pointers[561], &pointers[562], &pointers[563], &pointers[564], &pointers[565], &pointers[566], &pointers[567], &pointers[568], &pointers[569], &pointers[570], &pointers[571], &pointers[572], &pointers[573], &pointers[574], &pointers[575], &pointers[576], &pointers[577], &pointers[578], &pointers[579], &pointers[580], &pointers[581], &pointers[582], &pointers[583], &pointers[584], &pointers[585], &pointers[586], &pointers[587], &pointers[588], &pointers[589], &pointers[590], &pointers[591], &pointers[592], &pointers[593], &pointers[594], &pointers[595], &pointers[596], &pointers[597], &pointers[598], &pointers[599], &pointers[600],
  &pointers[601], &pointers[602], &pointers[603], &pointers[604], &pointers[605], &pointers[606], &pointers[607], &pointers[608], &pointers[609], &pointers[610], &pointers[611], &pointers[612], &pointers[613], &pointers[614], &pointers[615], &pointers[616], &pointers[617], &pointers[618], &pointers[619], &pointers[620], &pointers[621], &pointers[622], &pointers[623], &pointers[624], &pointers[625], &pointers[626], &pointers[627], &pointers[628], &pointers[629], &pointers[630], &pointers[631], &pointers[632], &pointers[633], &pointers[634], &pointers[635], &pointers[636], &pointers[637], &pointers[638], &pointers[639], &pointers[640], &pointers[641], &pointers[642], &pointers[643], &pointers[644], &pointers[645], &pointers[646], &pointers[647], &pointers[648], &pointers[649], &pointers[650],
  &pointers[651], &pointers[652], &pointers[653], &pointers[654], &pointers[655], &pointers[656], &pointers[657], &pointers[658], &pointers[659], &pointers[660], &pointers[661], &pointers[662], &pointers[663], &pointers[664], &pointers[665], &pointers[666], &pointers[667], &pointers[668], &pointers[669], &pointers[670], &pointers[671], &pointers[672], &pointers[673], &pointers[674], &pointers[675], &pointers[676], &pointers[677], &pointers[678], &pointers[679], &pointers[680], &pointers[681], &pointers[682], &pointers[683], &pointers[684], &pointers[685], &pointers[686], &pointers[687], &pointers[688], &pointers[689], &pointers[690], &pointers[691], &pointers[692], &pointers[693], &pointers[694], &pointers[695], &pointers[696], &pointers[697], &pointers[698], &pointers[699], &pointers[700],
  &pointers[701], &pointers[702], &pointers[703], &pointers[704], &pointers[705], &pointers[706], &pointers[707], &pointers[708], &pointers[709], &pointers[710], &pointers[711], &pointers[712], &pointers[713], &pointers[714], &pointers[715], &pointers[716], &pointers[717], &pointers[718], &pointers[719], &pointers[720], &pointers[721], &pointers[722], &pointers[723], &pointers[724], &pointers[725], &pointers[726], &pointers[727], &pointers[728], &pointers[729], &pointers[730], &pointers[731], &pointers[732], &pointers[733], &pointers[734], &pointers[735], &pointers[736], &pointers[737], &pointers[738], &pointers[739], &pointers[740], &pointers[741], &pointers[742], &pointers[743], &pointers[744], &pointers[745], &pointers[746], &pointers[747], &pointers[748], &pointers[749], &pointers[750],
  &pointers[751], &pointers[752], &pointers[753], &pointers[754], &pointers[755], &pointers[756], &pointers[757], &pointers[758], &pointers[759], &pointers[760], &pointers[761], &pointers[762], &pointers[763], &pointers[764], &pointers[765], &pointers[766], &pointers[767], &pointers[768], &pointers[769], &pointers[770], &pointers[771], &pointers[772], &pointers[773], &pointers[774], &pointers[775], &pointers[776], &pointers[777], &pointers[778], &pointers[779], &pointers[780], &pointers[781], &pointers[782], &pointers[783], &pointers[784], &pointers[785], &pointers[786], &pointers[787], &pointers[788], &pointers[789], &pointers[790], &pointers[791], &pointers[792], &pointers[793], &pointers[794], &pointers[795], &pointers[796], &pointers[797], &pointers[798], &pointers[799], &pointers[800],
  &pointers[801], &pointers[802], &pointers[803], &pointers[804], &pointers[805], &pointers[806], &pointers[807], &pointers[808], &pointers[809], &pointers[810], &pointers[811], &pointers[812], &pointers[813], &pointers[814], &pointers[815], &pointers[816], &pointers[817], &pointers[818], &pointers[819], &pointers[820], &pointers[821], &pointers[822], &pointers[823], &pointers[824], &pointers[825], &pointers[826], &pointers[827], &pointers[828], &pointers[829], &pointers[830], &pointers[831], &pointers[832], &pointers[833], &pointers[834], &pointers[835], &pointers[836], &pointers[837], &pointers[838], &pointers[839], &pointers[840], &pointers[841], &pointers[842], &pointers[843], &pointers[844], &pointers[845], &pointers[846], &pointers[847], &pointers[848], &pointers[849], &pointers[850],
  &pointers[851], &pointers[852], &pointers[853], &pointers[854], &pointers[855], &pointers[856], &pointers[857], &pointers[858], &pointers[859], &pointers[860], &pointers[861], &pointers[862], &pointers[863], &pointers[864], &pointers[865], &pointers[866], &pointers[867], &pointers[868], &pointers[869], &pointers[870], &pointers[871], &pointers[872], &pointers[873], &pointers[874], &pointers[875], &pointers[876], &pointers[877], &pointers[878], &pointers[879], &pointers[880], &pointers[881], &pointers[882], &pointers[883], &pointers[884], &pointers[885], &pointers[886], &pointers[887], &pointers[888], &pointers[889], &pointers[890], &pointers[891], &pointers[892], &pointers[893], &pointers[894], &pointers[895], &pointers[896], &pointers[897], &pointers[898], &pointers[899], &pointers[900],
  &pointers[901], &pointers[902], &pointers[903], &pointers[904], &pointers[905], &pointers[906], &pointers[907], &pointers[908], &pointers[909], &pointers[910], &pointers[911], &pointers[912], &pointers[913], &pointers[914], &pointers[915], &pointers[916], &pointers[917], &pointers[918], &pointers[919], &pointers[920], &pointers[921], &pointers[922], &pointers[923], &pointers[924], &pointers[925], &pointers[926], &pointers[927], &pointers[928], &pointers[929], &pointers[930], &pointers[931], &pointers[932], &pointers[933], &pointers[934], &pointers[935], &pointers[936], &pointers[937], &pointers[938], &pointers[939], &pointers[940], &pointers[941], &pointers[942], &pointers[943], &pointers[944], &pointers[945], &pointers[946], &pointers[947], &pointers[948], &pointers[949], &pointers[950],
  &pointers[951], &pointers[952], &pointers[953], &pointers[954], &pointers[955], &pointers[956], &pointers[957], &pointers[958], &pointers[959], &pointers[960], &pointers[961], &pointers[962], &pointers[963], &pointers[964], &pointers[965], &pointers[966], &pointers[967], &pointers[968], &pointers[969], &pointers[970], &pointers[971], &pointers[972], &pointers[973], &pointers[974], &pointers[975], &pointers[976], &pointers[977], &pointers[978], &pointers[979], &pointers[980], &pointers[981], &pointers[982], &pointers[983], &pointers[984], &pointers[985], &pointers[986], &pointers[987], &pointers[988], &pointers[989], &pointers[990], &pointers[991], &pointers[992], &pointers[993], &pointers[994], &pointers[995], &pointers[996], &pointers[997], &pointers[998], &pointers[999], &pointers[1000],
  &pointers[1001], &pointers[1002], &pointers[1003], &pointers[1004], &pointers[1005], &pointers[1006], &pointers[1007], &pointers[1008], &pointers[1009], &pointers[1010], &pointers[1011], &pointers[1012], &pointers[1013], &pointers[1014], &pointers[1015], &pointers[1016], &pointers[1017], &pointers[1018], &pointers[1019], &pointers[1020], &pointers[1021], &pointers[1022], &pointers[1023], &pointers[1024], &pointers[1025], &pointers[1026], &pointers[1027], &pointers[1028], &pointers[1029], &pointers[1030], &pointers[1031], &pointers[1032], &pointers[1033], &pointers[1034], &pointers[1035], &pointers[1036], &pointers[1037], &pointers[1038], &pointers[1039], &pointers[1040], &pointers[1041], &pointers[1042], &pointers[1043], &pointers[1044], &pointers[1045], &pointers[1046], &pointers[1047], &pointers[1048], &pointers[1049], &pointers[1050],
  &pointers[1051], &pointers[1052], &pointers[1053], &pointers[1054], &pointers[1055], &pointers[1056], &pointers[1057], &pointers[1058], &pointers[1059], &pointers[1060], &pointers[1061], &pointers[1062], &pointers[1063], &pointers[1064], &pointers[1065], &pointers[1066], &pointers[1067], &pointers[1068], &pointers[1069], &pointers[1070], &pointers[1071], &pointers[1072], &pointers[1073], &pointers[1074], &pointers[1075], &pointers[1076], &pointers[1077], &pointers[1078], &pointers[1079], &pointers[1080], &pointers[1081], &pointers[1082], &pointers[1083], &pointers[1084], &pointers[1085], &pointers[1086], &pointers[1087], &pointers[1088], &pointers[1089], &pointers[1090], &pointers[1091], &pointers[1092], &pointers[1093], &pointers[1094], &pointers[1095], &pointers[1096], &pointers[1097], &pointers[1098], &pointers[1099], &pointers[1100],
  &pointers[1101], &pointers[1102], &pointers[1103], &pointers[1104], &pointers[1105], &pointers[1106], &pointers[1107], &pointers[1108], &pointers[1109], &pointers[1110], &pointers[1111], &pointers[1112], &pointers[1113], &pointers[1114], &pointers[1115], &pointers[1116], &pointers[1117], &pointers[1118], &pointers[1119], &pointers[1120], &pointers[1121], &pointers[1122], &pointers[1123], &pointers[1124], &pointers[1125], &pointers[1126], &pointers[1127], &pointers[1128], &pointers[1129], &pointers[1130], &pointers[1131], &pointers[1132], &pointers[1133], &pointers[1134], &pointers[1135], &pointers[1136], &pointers[1137], &pointers[1138], &pointers[1139], &pointers[1140], &pointers[1141], &pointers[1142], &pointers[1143], &pointers[1144], &pointers[1145], &pointers[1146], &pointers[1147], &pointers[1148], &pointers[1149], &pointers[1150],
  &pointers[1151], &pointers[1152], &pointers[1153], &pointers[1154], &pointers[1155], &pointers[1156], &pointers[1157], &pointers[1158], &pointers[1159], &pointers[1160], &pointers[1161], &pointers[1162], &pointers[1163], &pointers[1164], &pointers[1165], &pointers[1166], &pointers[1167], &pointers[1168], &pointers[1169], &pointers[1170], &pointers[1171], &pointers[1172], &pointers[1173], &pointers[1174], &pointers[1175], &pointers[1176], &pointers[1177], &pointers[1178], &pointers[1179], &pointers[1180], &pointers[1181], &pointers[1182], &pointers[1183], &pointers[1184], &pointers[1185], &pointers[1186], &pointers[1187], &pointers[1188], &pointers[1189], &pointers[1190], &pointers[1191], &pointers[1192], &pointers[1193], &pointers[1194], &pointers[1195], &pointers[1196], &pointers[1197], &pointers[1198], &pointers[1199], &pointers[1200],
  &pointers[1201], &pointers[1202], &pointers[1203], &pointers[1204], &pointers[1205], &pointers[1206], &pointers[1207], &pointers[1208], &pointers[1209], &pointers[1210], &pointers[1211], &pointers[1212], &pointers[1213], &pointers[1214], &pointers[1215], &pointers[1216], &pointers[1217], &pointers[1218], &pointers[1219], &pointers[1220], &pointers[1221], &pointers[1222], &pointers[1223], &pointers[1224], &pointers[1225], &pointers[1226], &pointers[1227], &pointers[1228], &pointers[1229], &pointers[1230], &pointers[1231], &pointers[1232], &pointers[1233], &pointers[1234], &pointers[1235], &pointers[1236], &pointers[1237], &pointers[1238], &pointers[1239], &pointers[1240], &pointers[1241], &pointers[1242], &pointers[1243], &pointers[1244], &pointers[1245], &pointers[1246], &pointers[1247], &pointers[1248], &pointers[1249], &pointers[1250],
  &pointers[1251], &pointers[1252], &pointers[1253], &pointers[1254], &pointers[1255], &pointers[1256], &pointers[1257], &pointers[1258], &pointers[1259], &pointers[1260], &pointers[1261], &pointers[1262], &pointers[1263], &pointers[1264], &pointers[1265], &pointers[1266], &pointers[1267], &pointers[1268], &pointers[1269], &pointers[1270], &pointers[1271], &pointers[1272], &pointers[1273], &pointers[1274], &pointers[1275], &pointers[1276], &pointers[1277], &pointers[1278], &pointers[1279], &pointers[1280], &pointers[1281], &pointers[1282], &pointers[1283], &pointers[1284], &pointers[1285], &pointers[1286], &pointers[1287], &pointers[1288], &pointers[1289], &pointers[1290], &pointers[1291], &pointers[1292], &pointers[1293], &pointers[1294], &pointers[1295], &pointers[1296], &pointers[1297], &pointers[1298], &pointers[1299], &pointers[1300],
  &pointers[1301], &pointers[1302], &pointers[1303], &pointers[1304], &pointers[1305], &pointers[1306], &pointers[1307], &pointers[1308], &pointers[1309], &pointers[1310], &pointers[1311], &pointers[1312], &pointers[1313], &pointers[1314], &pointers[1315], &pointers[1316], &pointers[1317], &pointers[1318], &pointers[1319], &pointers[1320], &pointers[1321], &pointers[1322], &pointers[1323], &pointers[1324], &pointers[1325], &pointers[1326], &pointers[1327], &pointers[1328], &pointers[1329], &pointers[1330], &pointers[1331], &pointers[1332], &pointers[1333], &pointers[1334], &pointers[1335], &pointers[1336], &pointers[1337], &pointers[1338], &pointers[1339], &pointers[1340], &pointers[1341], &pointers[1342], &pointers[1343], &pointers[1344], &pointers[1345], &pointers[1346], &pointers[1347], &pointers[1348], &pointers[1349], &pointers[1350],
  &pointers[1351], &pointers[1352], &pointers[1353], &pointers[1354], &pointers[1355], &pointers[1356], &pointers[1357], &pointers[1358], &pointers[1359], &pointers[1360], &pointers[1361], &pointers[1362], &pointers[1363], &pointers[1364], &pointers[1365], &pointers[1366], &pointers[1367], &pointers[1368], &pointers[1369], &pointers[1370], &pointers[1371], &pointers[1372], &pointers[1373], &pointers[1374], &pointers[1375], &pointers[1376], &pointers[1377], &pointers[1378], &pointers[1379], &pointers[1380], &pointers[1381], &pointers[1382], &pointers[1383], &pointers[1384], &pointers[1385], &pointers[1386], &pointers[1387], &pointers[1388], &pointers[1389], &pointers[1390], &pointers[1391], &pointers[1392], &pointers[1393], &pointers[1394], &pointers[1395], &pointers[1396], &pointers[1397], &pointers[1398], &pointers[1399], &pointers[1400],
  &pointers[1401], &pointers[1402], &pointers[1403], &pointers[1404], &pointers[1405], &pointers[1406], &pointers[1407], &pointers[1408], &pointers[1409], &pointers[1410], &pointers[1411], &pointers[1412], &pointers[1413], &pointers[1414], &pointers[1415], &pointers[1416], &pointers[1417], &pointers[1418], &pointers[1419], &pointers[1420], &pointers[1421], &pointers[1422], &pointers[1423], &pointers[1424], &pointers[1425], &pointers[1426], &pointers[1427], &pointers[1428], &pointers[1429], &pointers[1430], &pointers[1431], &pointers[1432], &pointers[1433], &pointers[1434], &pointers[1435], &pointers[1436], &pointers[1437], &pointers[1438], &pointers[1439], &pointers[1440], &pointers[1441], &pointers[1442], &pointers[1443], &pointers[1444], &pointers[1445], &pointers[1446], &pointers[1447], &pointers[1448], &pointers[1449], &pointers[1450],
  &pointers[1451], &pointers[1452], &pointers[1453], &pointers[1454], &pointers[1455], &pointers[1456], &pointers[1457], &pointers[1458], &pointers[1459], &pointers[1460], &pointers[1461], &pointers[1462], &pointers[1463], &pointers[1464], &pointers[1465], &pointers[1466], &pointers[1467], &pointers[1468], &pointers[1469], &pointers[1470], &pointers[1471], &pointers[1472], &pointers[1473], &pointers[1474], &pointers[1475], &pointers[1476], &pointers[1477], &pointers[1478], &pointers[1479], &pointers[1480], &pointers[1481], &pointers[1482], &pointers[1483], &pointers[1484], &pointers[1485], &pointers[1486], &pointers[1487], &pointers[1488], &pointers[1489], &pointers[1490], &pointers[1491], &pointers[1492], &pointers[1493], &pointers[1494], &pointers[1495], &pointers[1496], &pointers[1497], &pointers[1498], &pointers[1499], &pointers[1500],
  &pointers[1501], &pointers[1502], &pointers[1503], &pointers[1504], &pointers[1505], &pointers[1506], &pointers[1507], &pointers[1508], &pointers[1509], &pointers[1510], &pointers[1511], &pointers[1512], &pointers[1513], &pointers[1514], &pointers[1515], &pointers[1516], &pointers[1517], &pointers[1518], &pointers[1519], &pointers[1520], &pointers[1521], &pointers[1522], &pointers[1523], &pointers[1524], &pointers[1525], &pointers[1526], &pointers[1527], &pointers[1528], &pointers[1529], &pointers[1530], &pointers[1531], &pointers[1532], &pointers[1533], &pointers[1534], &pointers[1535], &pointers[1536], &pointers[1537], &pointers[1538], &pointers[1539], &pointers[1540], &pointers[1541], &pointers[1542], &pointers[1543], &pointers[1544], &pointers[1545], &pointers[1546], &pointers[1547], &pointers[1548], &pointers[1549], &pointers[1550],
  &pointers[1551], &pointers[1552], &pointers[1553], &pointers[1554], &pointers[1555], &pointers[1556], &pointers[1557], &pointers[1558], &pointers[1559], &pointers[1560], &pointers[1561], &pointers[1562], &pointers[1563], &pointers[1564], &pointers[1565], &pointers[1566], &pointers[1567], &pointers[1568], &pointers[1569], &pointers[1570], &pointers[1571], &pointers[1572], &pointers[1573], &pointers[1574], &pointers[1575], &pointers[1576], &pointers[1577], &pointers[1578], &pointers[1579], &pointers[1580], &pointers[1581], &pointers[1582], &pointers[1583], &pointers[1584], &pointers[1585], &pointers[1586], &pointers[1587], &pointers[1588], &pointers[1589], &pointers[1590], &pointers[1591], &pointers[1592], &pointers[1593], &pointers[1594], &pointers[1595], &pointers[1596], &pointers[1597], &pointers[1598], &pointers[1599], &pointers[1600],
  &pointers[1601], &pointers[1602], &pointers[1603], &pointers[1604], &pointers[1605], &pointers[1606], &pointers[1607], &pointers[1608], &pointers[1609], &pointers[1610], &pointers[1611], &pointers[1612], &pointers[1613], &pointers[1614], &pointers[1615], &pointers[1616], &pointers[1617], &pointers[1618], &pointers[1619], &pointers[1620], &pointers[1621], &pointers[1622], &pointers[1623], &pointers[1624], &pointers[1625], &pointers[1626], &pointers[1627], &pointers[1628], &pointers[1629], &pointers[1630], &pointers[1631], &pointers[1632], &pointers[1633], &pointers[1634], &pointers[1635], &pointers[1636], &pointers[1637], &pointers[1638], &pointers[1639], &pointers[1640], &pointers[1641], &pointers[1642], &pointers[1643], &pointers[1644], &pointers[1645], &pointers[1646], &pointers[1647], &pointers[1648], &pointers[1649], &pointers[1650],
  &pointers[1651], &pointers[1652], &pointers[1653], &pointers[1654], &pointers[1655], &pointers[1656], &pointers[1657], &pointers[1658], &pointers[1659], &pointers[1660], &pointers[1661], &pointers[1662], &pointers[1663], &pointers[1664], &pointers[1665], &pointers[1666], &pointers[1667], &pointers[1668], &pointers[1669], &pointers[1670], &pointers[1671], &pointers[1672], &pointers[1673], &pointers[1674], &pointers[1675], &pointers[1676], &pointers[1677], &pointers[1678], &pointers[1679], &pointers[1680], &pointers[1681], &pointers[1682], &pointers[1683], &pointers[1684], &pointers[1685], &pointers[1686], &pointers[1687], &pointers[1688], &pointers[1689], &pointers[1690], &pointers[1691], &pointers[1692], &pointers[1693], &pointers[1694], &pointers[1695], &pointers[1696], &pointers[1697], &pointers[1698], &pointers[1699], &pointers[1700],
  &pointers[1701], &pointers[1702], &pointers[1703], &pointers[1704], &pointers[1705], &pointers[1706], &pointers[1707], &pointers[1708], &pointers[1709], &pointers[1710], &pointers[1711], &pointers[1712], &pointers[1713], &pointers[1714], &pointers[1715], &pointers[1716], &pointers[1717], &pointers[1718], &pointers[1719], &pointers[1720], &pointers[1721], &pointers[1722], &pointers[1723], &pointers[1724], &pointers[1725], &pointers[1726], &pointers[1727], &pointers[1728], &pointers[1729], &pointers[1730], &pointers[1731], &pointers[1732], &pointers[1733], &pointers[1734], &pointers[1735], &pointers[1736], &pointers[1737], &pointers[1738], &pointers[1739], &pointers[1740], &pointers[1741], &pointers[1742], &pointers[1743], &pointers[1744], &pointers[1745], &pointers[1746], &pointers[1747], &pointers[1748], &pointers[1749], NULL };
#endif

#ifdef POINTER_SIZE_2000
#ifdef FUNCTIONS_DATA_ON_CCM
  __attribute__((section(".ccmramdata")))
#endif
#ifdef FUNCTIONS_DATA_ON_FLASH
  const
#endif
   void *
#ifdef FUNCTIONS_DATA_ON_FLASH
  const
#endif
  pointers[2000] = {
  &pointers[1], &pointers[2], &pointers[3], &pointers[4], &pointers[5], &pointers[6], &pointers[7], &pointers[8], &pointers[9], &pointers[10], &pointers[11], &pointers[12], &pointers[13], &pointers[14], &pointers[15], &pointers[16], &pointers[17], &pointers[18], &pointers[19], &pointers[20], &pointers[21], &pointers[22], &pointers[23], &pointers[24], &pointers[25], &pointers[26], &pointers[27], &pointers[28], &pointers[29], &pointers[30], &pointers[31], &pointers[32], &pointers[33], &pointers[34], &pointers[35], &pointers[36], &pointers[37], &pointers[38], &pointers[39], &pointers[40], &pointers[41], &pointers[42], &pointers[43], &pointers[44], &pointers[45], &pointers[46], &pointers[47], &pointers[48], &pointers[49], &pointers[50],
  &pointers[51], &pointers[52], &pointers[53], &pointers[54], &pointers[55], &pointers[56], &pointers[57], &pointers[58], &pointers[59], &pointers[60], &pointers[61], &pointers[62], &pointers[63], &pointers[64], &pointers[65], &pointers[66], &pointers[67], &pointers[68], &pointers[69], &pointers[70], &pointers[71], &pointers[72], &pointers[73], &pointers[74], &pointers[75], &pointers[76], &pointers[77], &pointers[78], &pointers[79], &pointers[80], &pointers[81], &pointers[82], &pointers[83], &pointers[84], &pointers[85], &pointers[86], &pointers[87], &pointers[88], &pointers[89], &pointers[90], &pointers[91], &pointers[92], &pointers[93], &pointers[94], &pointers[95], &pointers[96], &pointers[97], &pointers[98], &pointers[99], &pointers[100],
  &pointers[101], &pointers[102], &pointers[103], &pointers[104], &pointers[105], &pointers[106], &pointers[107], &pointers[108], &pointers[109], &pointers[110], &pointers[111], &pointers[112], &pointers[113], &pointers[114], &pointers[115], &pointers[116], &pointers[117], &pointers[118], &pointers[119], &pointers[120], &pointers[121], &pointers[122], &pointers[123], &pointers[124], &pointers[125], &pointers[126], &pointers[127], &pointers[128], &pointers[129], &pointers[130], &pointers[131], &pointers[132], &pointers[133], &pointers[134], &pointers[135], &pointers[136], &pointers[137], &pointers[138], &pointers[139], &pointers[140], &pointers[141], &pointers[142], &pointers[143], &pointers[144], &pointers[145], &pointers[146], &pointers[147], &pointers[148], &pointers[149], &pointers[150],
  &pointers[151], &pointers[152], &pointers[153], &pointers[154], &pointers[155], &pointers[156], &pointers[157], &pointers[158], &pointers[159], &pointers[160], &pointers[161], &pointers[162], &pointers[163], &pointers[164], &pointers[165], &pointers[166], &pointers[167], &pointers[168], &pointers[169], &pointers[170], &pointers[171], &pointers[172], &pointers[173], &pointers[174], &pointers[175], &pointers[176], &pointers[177], &pointers[178], &pointers[179], &pointers[180], &pointers[181], &pointers[182], &pointers[183], &pointers[184], &pointers[185], &pointers[186], &pointers[187], &pointers[188], &pointers[189], &pointers[190], &pointers[191], &pointers[192], &pointers[193], &pointers[194], &pointers[195], &pointers[196], &pointers[197], &pointers[198], &pointers[199], &pointers[200],
  &pointers[201], &pointers[202], &pointers[203], &pointers[204], &pointers[205], &pointers[206], &pointers[207], &pointers[208], &pointers[209], &pointers[210], &pointers[211], &pointers[212], &pointers[213], &pointers[214], &pointers[215], &pointers[216], &pointers[217], &pointers[218], &pointers[219], &pointers[220], &pointers[221], &pointers[222], &pointers[223], &pointers[224], &pointers[225], &pointers[226], &pointers[227], &pointers[228], &pointers[229], &pointers[230], &pointers[231], &pointers[232], &pointers[233], &pointers[234], &pointers[235], &pointers[236], &pointers[237], &pointers[238], &pointers[239], &pointers[240], &pointers[241], &pointers[242], &pointers[243], &pointers[244], &pointers[245], &pointers[246], &pointers[247], &pointers[248], &pointers[249], &pointers[250],
  &pointers[251], &pointers[252], &pointers[253], &pointers[254], &pointers[255], &pointers[256], &pointers[257], &pointers[258], &pointers[259], &pointers[260], &pointers[261], &pointers[262], &pointers[263], &pointers[264], &pointers[265], &pointers[266], &pointers[267], &pointers[268], &pointers[269], &pointers[270], &pointers[271], &pointers[272], &pointers[273], &pointers[274], &pointers[275], &pointers[276], &pointers[277], &pointers[278], &pointers[279], &pointers[280], &pointers[281], &pointers[282], &pointers[283], &pointers[284], &pointers[285], &pointers[286], &pointers[287], &pointers[288], &pointers[289], &pointers[290], &pointers[291], &pointers[292], &pointers[293], &pointers[294], &pointers[295], &pointers[296], &pointers[297], &pointers[298], &pointers[299], &pointers[300],
  &pointers[301], &pointers[302], &pointers[303], &pointers[304], &pointers[305], &pointers[306], &pointers[307], &pointers[308], &pointers[309], &pointers[310], &pointers[311], &pointers[312], &pointers[313], &pointers[314], &pointers[315], &pointers[316], &pointers[317], &pointers[318], &pointers[319], &pointers[320], &pointers[321], &pointers[322], &pointers[323], &pointers[324], &pointers[325], &pointers[326], &pointers[327], &pointers[328], &pointers[329], &pointers[330], &pointers[331], &pointers[332], &pointers[333], &pointers[334], &pointers[335], &pointers[336], &pointers[337], &pointers[338], &pointers[339], &pointers[340], &pointers[341], &pointers[342], &pointers[343], &pointers[344], &pointers[345], &pointers[346], &pointers[347], &pointers[348], &pointers[349], &pointers[350],
  &pointers[351], &pointers[352], &pointers[353], &pointers[354], &pointers[355], &pointers[356], &pointers[357], &pointers[358], &pointers[359], &pointers[360], &pointers[361], &pointers[362], &pointers[363], &pointers[364], &pointers[365], &pointers[366], &pointers[367], &pointers[368], &pointers[369], &pointers[370], &pointers[371], &pointers[372], &pointers[373], &pointers[374], &pointers[375], &pointers[376], &pointers[377], &pointers[378], &pointers[379], &pointers[380], &pointers[381], &pointers[382], &pointers[383], &pointers[384], &pointers[385], &pointers[386], &pointers[387], &pointers[388], &pointers[389], &pointers[390], &pointers[391], &pointers[392], &pointers[393], &pointers[394], &pointers[395], &pointers[396], &pointers[397], &pointers[398], &pointers[399], &pointers[400],
  &pointers[401], &pointers[402], &pointers[403], &pointers[404], &pointers[405], &pointers[406], &pointers[407], &pointers[408], &pointers[409], &pointers[410], &pointers[411], &pointers[412], &pointers[413], &pointers[414], &pointers[415], &pointers[416], &pointers[417], &pointers[418], &pointers[419], &pointers[420], &pointers[421], &pointers[422], &pointers[423], &pointers[424], &pointers[425], &pointers[426], &pointers[427], &pointers[428], &pointers[429], &pointers[430], &pointers[431], &pointers[432], &pointers[433], &pointers[434], &pointers[435], &pointers[436], &pointers[437], &pointers[438], &pointers[439], &pointers[440], &pointers[441], &pointers[442], &pointers[443], &pointers[444], &pointers[445], &pointers[446], &pointers[447], &pointers[448], &pointers[449], &pointers[450],
  &pointers[451], &pointers[452], &pointers[453], &pointers[454], &pointers[455], &pointers[456], &pointers[457], &pointers[458], &pointers[459], &pointers[460], &pointers[461], &pointers[462], &pointers[463], &pointers[464], &pointers[465], &pointers[466], &pointers[467], &pointers[468], &pointers[469], &pointers[470], &pointers[471], &pointers[472], &pointers[473], &pointers[474], &pointers[475], &pointers[476], &pointers[477], &pointers[478], &pointers[479], &pointers[480], &pointers[481], &pointers[482], &pointers[483], &pointers[484], &pointers[485], &pointers[486], &pointers[487], &pointers[488], &pointers[489], &pointers[490], &pointers[491], &pointers[492], &pointers[493], &pointers[494], &pointers[495], &pointers[496], &pointers[497], &pointers[498], &pointers[499], &pointers[500],
  &pointers[501], &pointers[502], &pointers[503], &pointers[504], &pointers[505], &pointers[506], &pointers[507], &pointers[508], &pointers[509], &pointers[510], &pointers[511], &pointers[512], &pointers[513], &pointers[514], &pointers[515], &pointers[516], &pointers[517], &pointers[518], &pointers[519], &pointers[520], &pointers[521], &pointers[522], &pointers[523], &pointers[524], &pointers[525], &pointers[526], &pointers[527], &pointers[528], &pointers[529], &pointers[530], &pointers[531], &pointers[532], &pointers[533], &pointers[534], &pointers[535], &pointers[536], &pointers[537], &pointers[538], &pointers[539], &pointers[540], &pointers[541], &pointers[542], &pointers[543], &pointers[544], &pointers[545], &pointers[546], &pointers[547], &pointers[548], &pointers[549], &pointers[550],
  &pointers[551], &pointers[552], &pointers[553], &pointers[554], &pointers[555], &pointers[556], &pointers[557], &pointers[558], &pointers[559], &pointers[560], &pointers[561], &pointers[562], &pointers[563], &pointers[564], &pointers[565], &pointers[566], &pointers[567], &pointers[568], &pointers[569], &pointers[570], &pointers[571], &pointers[572], &pointers[573], &pointers[574], &pointers[575], &pointers[576], &pointers[577], &pointers[578], &pointers[579], &pointers[580], &pointers[581], &pointers[582], &pointers[583], &pointers[584], &pointers[585], &pointers[586], &pointers[587], &pointers[588], &pointers[589], &pointers[590], &pointers[591], &pointers[592], &pointers[593], &pointers[594], &pointers[595], &pointers[596], &pointers[597], &pointers[598], &pointers[599], &pointers[600],
  &pointers[601], &pointers[602], &pointers[603], &pointers[604], &pointers[605], &pointers[606], &pointers[607], &pointers[608], &pointers[609], &pointers[610], &pointers[611], &pointers[612], &pointers[613], &pointers[614], &pointers[615], &pointers[616], &pointers[617], &pointers[618], &pointers[619], &pointers[620], &pointers[621], &pointers[622], &pointers[623], &pointers[624], &pointers[625], &pointers[626], &pointers[627], &pointers[628], &pointers[629], &pointers[630], &pointers[631], &pointers[632], &pointers[633], &pointers[634], &pointers[635], &pointers[636], &pointers[637], &pointers[638], &pointers[639], &pointers[640], &pointers[641], &pointers[642], &pointers[643], &pointers[644], &pointers[645], &pointers[646], &pointers[647], &pointers[648], &pointers[649], &pointers[650],
  &pointers[651], &pointers[652], &pointers[653], &pointers[654], &pointers[655], &pointers[656], &pointers[657], &pointers[658], &pointers[659], &pointers[660], &pointers[661], &pointers[662], &pointers[663], &pointers[664], &pointers[665], &pointers[666], &pointers[667], &pointers[668], &pointers[669], &pointers[670], &pointers[671], &pointers[672], &pointers[673], &pointers[674], &pointers[675], &pointers[676], &pointers[677], &pointers[678], &pointers[679], &pointers[680], &pointers[681], &pointers[682], &pointers[683], &pointers[684], &pointers[685], &pointers[686], &pointers[687], &pointers[688], &pointers[689], &pointers[690], &pointers[691], &pointers[692], &pointers[693], &pointers[694], &pointers[695], &pointers[696], &pointers[697], &pointers[698], &pointers[699], &pointers[700],
  &pointers[701], &pointers[702], &pointers[703], &pointers[704], &pointers[705], &pointers[706], &pointers[707], &pointers[708], &pointers[709], &pointers[710], &pointers[711], &pointers[712], &pointers[713], &pointers[714], &pointers[715], &pointers[716], &pointers[717], &pointers[718], &pointers[719], &pointers[720], &pointers[721], &pointers[722], &pointers[723], &pointers[724], &pointers[725], &pointers[726], &pointers[727], &pointers[728], &pointers[729], &pointers[730], &pointers[731], &pointers[732], &pointers[733], &pointers[734], &pointers[735], &pointers[736], &pointers[737], &pointers[738], &pointers[739], &pointers[740], &pointers[741], &pointers[742], &pointers[743], &pointers[744], &pointers[745], &pointers[746], &pointers[747], &pointers[748], &pointers[749], &pointers[750],
  &pointers[751], &pointers[752], &pointers[753], &pointers[754], &pointers[755], &pointers[756], &pointers[757], &pointers[758], &pointers[759], &pointers[760], &pointers[761], &pointers[762], &pointers[763], &pointers[764], &pointers[765], &pointers[766], &pointers[767], &pointers[768], &pointers[769], &pointers[770], &pointers[771], &pointers[772], &pointers[773], &pointers[774], &pointers[775], &pointers[776], &pointers[777], &pointers[778], &pointers[779], &pointers[780], &pointers[781], &pointers[782], &pointers[783], &pointers[784], &pointers[785], &pointers[786], &pointers[787], &pointers[788], &pointers[789], &pointers[790], &pointers[791], &pointers[792], &pointers[793], &pointers[794], &pointers[795], &pointers[796], &pointers[797], &pointers[798], &pointers[799], &pointers[800],
  &pointers[801], &pointers[802], &pointers[803], &pointers[804], &pointers[805], &pointers[806], &pointers[807], &pointers[808], &pointers[809], &pointers[810], &pointers[811], &pointers[812], &pointers[813], &pointers[814], &pointers[815], &pointers[816], &pointers[817], &pointers[818], &pointers[819], &pointers[820], &pointers[821], &pointers[822], &pointers[823], &pointers[824], &pointers[825], &pointers[826], &pointers[827], &pointers[828], &pointers[829], &pointers[830], &pointers[831], &pointers[832], &pointers[833], &pointers[834], &pointers[835], &pointers[836], &pointers[837], &pointers[838], &pointers[839], &pointers[840], &pointers[841], &pointers[842], &pointers[843], &pointers[844], &pointers[845], &pointers[846], &pointers[847], &pointers[848], &pointers[849], &pointers[850],
  &pointers[851], &pointers[852], &pointers[853], &pointers[854], &pointers[855], &pointers[856], &pointers[857], &pointers[858], &pointers[859], &pointers[860], &pointers[861], &pointers[862], &pointers[863], &pointers[864], &pointers[865], &pointers[866], &pointers[867], &pointers[868], &pointers[869], &pointers[870], &pointers[871], &pointers[872], &pointers[873], &pointers[874], &pointers[875], &pointers[876], &pointers[877], &pointers[878], &pointers[879], &pointers[880], &pointers[881], &pointers[882], &pointers[883], &pointers[884], &pointers[885], &pointers[886], &pointers[887], &pointers[888], &pointers[889], &pointers[890], &pointers[891], &pointers[892], &pointers[893], &pointers[894], &pointers[895], &pointers[896], &pointers[897], &pointers[898], &pointers[899], &pointers[900],
  &pointers[901], &pointers[902], &pointers[903], &pointers[904], &pointers[905], &pointers[906], &pointers[907], &pointers[908], &pointers[909], &pointers[910], &pointers[911], &pointers[912], &pointers[913], &pointers[914], &pointers[915], &pointers[916], &pointers[917], &pointers[918], &pointers[919], &pointers[920], &pointers[921], &pointers[922], &pointers[923], &pointers[924], &pointers[925], &pointers[926], &pointers[927], &pointers[928], &pointers[929], &pointers[930], &pointers[931], &pointers[932], &pointers[933], &pointers[934], &pointers[935], &pointers[936], &pointers[937], &pointers[938], &pointers[939], &pointers[940], &pointers[941], &pointers[942], &pointers[943], &pointers[944], &pointers[945], &pointers[946], &pointers[947], &pointers[948], &pointers[949], &pointers[950],
  &pointers[951], &pointers[952], &pointers[953], &pointers[954], &pointers[955], &pointers[956], &pointers[957], &pointers[958], &pointers[959], &pointers[960], &pointers[961], &pointers[962], &pointers[963], &pointers[964], &pointers[965], &pointers[966], &pointers[967], &pointers[968], &pointers[969], &pointers[970], &pointers[971], &pointers[972], &pointers[973], &pointers[974], &pointers[975], &pointers[976], &pointers[977], &pointers[978], &pointers[979], &pointers[980], &pointers[981], &pointers[982], &pointers[983], &pointers[984], &pointers[985], &pointers[986], &pointers[987], &pointers[988], &pointers[989], &pointers[990], &pointers[991], &pointers[992], &pointers[993], &pointers[994], &pointers[995], &pointers[996], &pointers[997], &pointers[998], &pointers[999], &pointers[1000],
  &pointers[1001], &pointers[1002], &pointers[1003], &pointers[1004], &pointers[1005], &pointers[1006], &pointers[1007], &pointers[1008], &pointers[1009], &pointers[1010], &pointers[1011], &pointers[1012], &pointers[1013], &pointers[1014], &pointers[1015], &pointers[1016], &pointers[1017], &pointers[1018], &pointers[1019], &pointers[1020], &pointers[1021], &pointers[1022], &pointers[1023], &pointers[1024], &pointers[1025], &pointers[1026], &pointers[1027], &pointers[1028], &pointers[1029], &pointers[1030], &pointers[1031], &pointers[1032], &pointers[1033], &pointers[1034], &pointers[1035], &pointers[1036], &pointers[1037], &pointers[1038], &pointers[1039], &pointers[1040], &pointers[1041], &pointers[1042], &pointers[1043], &pointers[1044], &pointers[1045], &pointers[1046], &pointers[1047], &pointers[1048], &pointers[1049], &pointers[1050],
  &pointers[1051], &pointers[1052], &pointers[1053], &pointers[1054], &pointers[1055], &pointers[1056], &pointers[1057], &pointers[1058], &pointers[1059], &pointers[1060], &pointers[1061], &pointers[1062], &pointers[1063], &pointers[1064], &pointers[1065], &pointers[1066], &pointers[1067], &pointers[1068], &pointers[1069], &pointers[1070], &pointers[1071], &pointers[1072], &pointers[1073], &pointers[1074], &pointers[1075], &pointers[1076], &pointers[1077], &pointers[1078], &pointers[1079], &pointers[1080], &pointers[1081], &pointers[1082], &pointers[1083], &pointers[1084], &pointers[1085], &pointers[1086], &pointers[1087], &pointers[1088], &pointers[1089], &pointers[1090], &pointers[1091], &pointers[1092], &pointers[1093], &pointers[1094], &pointers[1095], &pointers[1096], &pointers[1097], &pointers[1098], &pointers[1099], &pointers[1100],
  &pointers[1101], &pointers[1102], &pointers[1103], &pointers[1104], &pointers[1105], &pointers[1106], &pointers[1107], &pointers[1108], &pointers[1109], &pointers[1110], &pointers[1111], &pointers[1112], &pointers[1113], &pointers[1114], &pointers[1115], &pointers[1116], &pointers[1117], &pointers[1118], &pointers[1119], &pointers[1120], &pointers[1121], &pointers[1122], &pointers[1123], &pointers[1124], &pointers[1125], &pointers[1126], &pointers[1127], &pointers[1128], &pointers[1129], &pointers[1130], &pointers[1131], &pointers[1132], &pointers[1133], &pointers[1134], &pointers[1135], &pointers[1136], &pointers[1137], &pointers[1138], &pointers[1139], &pointers[1140], &pointers[1141], &pointers[1142], &pointers[1143], &pointers[1144], &pointers[1145], &pointers[1146], &pointers[1147], &pointers[1148], &pointers[1149], &pointers[1150],
  &pointers[1151], &pointers[1152], &pointers[1153], &pointers[1154], &pointers[1155], &pointers[1156], &pointers[1157], &pointers[1158], &pointers[1159], &pointers[1160], &pointers[1161], &pointers[1162], &pointers[1163], &pointers[1164], &pointers[1165], &pointers[1166], &pointers[1167], &pointers[1168], &pointers[1169], &pointers[1170], &pointers[1171], &pointers[1172], &pointers[1173], &pointers[1174], &pointers[1175], &pointers[1176], &pointers[1177], &pointers[1178], &pointers[1179], &pointers[1180], &pointers[1181], &pointers[1182], &pointers[1183], &pointers[1184], &pointers[1185], &pointers[1186], &pointers[1187], &pointers[1188], &pointers[1189], &pointers[1190], &pointers[1191], &pointers[1192], &pointers[1193], &pointers[1194], &pointers[1195], &pointers[1196], &pointers[1197], &pointers[1198], &pointers[1199], &pointers[1200],
  &pointers[1201], &pointers[1202], &pointers[1203], &pointers[1204], &pointers[1205], &pointers[1206], &pointers[1207], &pointers[1208], &pointers[1209], &pointers[1210], &pointers[1211], &pointers[1212], &pointers[1213], &pointers[1214], &pointers[1215], &pointers[1216], &pointers[1217], &pointers[1218], &pointers[1219], &pointers[1220], &pointers[1221], &pointers[1222], &pointers[1223], &pointers[1224], &pointers[1225], &pointers[1226], &pointers[1227], &pointers[1228], &pointers[1229], &pointers[1230], &pointers[1231], &pointers[1232], &pointers[1233], &pointers[1234], &pointers[1235], &pointers[1236], &pointers[1237], &pointers[1238], &pointers[1239], &pointers[1240], &pointers[1241], &pointers[1242], &pointers[1243], &pointers[1244], &pointers[1245], &pointers[1246], &pointers[1247], &pointers[1248], &pointers[1249], &pointers[1250],
  &pointers[1251], &pointers[1252], &pointers[1253], &pointers[1254], &pointers[1255], &pointers[1256], &pointers[1257], &pointers[1258], &pointers[1259], &pointers[1260], &pointers[1261], &pointers[1262], &pointers[1263], &pointers[1264], &pointers[1265], &pointers[1266], &pointers[1267], &pointers[1268], &pointers[1269], &pointers[1270], &pointers[1271], &pointers[1272], &pointers[1273], &pointers[1274], &pointers[1275], &pointers[1276], &pointers[1277], &pointers[1278], &pointers[1279], &pointers[1280], &pointers[1281], &pointers[1282], &pointers[1283], &pointers[1284], &pointers[1285], &pointers[1286], &pointers[1287], &pointers[1288], &pointers[1289], &pointers[1290], &pointers[1291], &pointers[1292], &pointers[1293], &pointers[1294], &pointers[1295], &pointers[1296], &pointers[1297], &pointers[1298], &pointers[1299], &pointers[1300],
  &pointers[1301], &pointers[1302], &pointers[1303], &pointers[1304], &pointers[1305], &pointers[1306], &pointers[1307], &pointers[1308], &pointers[1309], &pointers[1310], &pointers[1311], &pointers[1312], &pointers[1313], &pointers[1314], &pointers[1315], &pointers[1316], &pointers[1317], &pointers[1318], &pointers[1319], &pointers[1320], &pointers[1321], &pointers[1322], &pointers[1323], &pointers[1324], &pointers[1325], &pointers[1326], &pointers[1327], &pointers[1328], &pointers[1329], &pointers[1330], &pointers[1331], &pointers[1332], &pointers[1333], &pointers[1334], &pointers[1335], &pointers[1336], &pointers[1337], &pointers[1338], &pointers[1339], &pointers[1340], &pointers[1341], &pointers[1342], &pointers[1343], &pointers[1344], &pointers[1345], &pointers[1346], &pointers[1347], &pointers[1348], &pointers[1349], &pointers[1350],
  &pointers[1351], &pointers[1352], &pointers[1353], &pointers[1354], &pointers[1355], &pointers[1356], &pointers[1357], &pointers[1358], &pointers[1359], &pointers[1360], &pointers[1361], &pointers[1362], &pointers[1363], &pointers[1364], &pointers[1365], &pointers[1366], &pointers[1367], &pointers[1368], &pointers[1369], &pointers[1370], &pointers[1371], &pointers[1372], &pointers[1373], &pointers[1374], &pointers[1375], &pointers[1376], &pointers[1377], &pointers[1378], &pointers[1379], &pointers[1380], &pointers[1381], &pointers[1382], &pointers[1383], &pointers[1384], &pointers[1385], &pointers[1386], &pointers[1387], &pointers[1388], &pointers[1389], &pointers[1390], &pointers[1391], &pointers[1392], &pointers[1393], &pointers[1394], &pointers[1395], &pointers[1396], &pointers[1397], &pointers[1398], &pointers[1399], &pointers[1400],
  &pointers[1401], &pointers[1402], &pointers[1403], &pointers[1404], &pointers[1405], &pointers[1406], &pointers[1407], &pointers[1408], &pointers[1409], &pointers[1410], &pointers[1411], &pointers[1412], &pointers[1413], &pointers[1414], &pointers[1415], &pointers[1416], &pointers[1417], &pointers[1418], &pointers[1419], &pointers[1420], &pointers[1421], &pointers[1422], &pointers[1423], &pointers[1424], &pointers[1425], &pointers[1426], &pointers[1427], &pointers[1428], &pointers[1429], &pointers[1430], &pointers[1431], &pointers[1432], &pointers[1433], &pointers[1434], &pointers[1435], &pointers[1436], &pointers[1437], &pointers[1438], &pointers[1439], &pointers[1440], &pointers[1441], &pointers[1442], &pointers[1443], &pointers[1444], &pointers[1445], &pointers[1446], &pointers[1447], &pointers[1448], &pointers[1449], &pointers[1450],
  &pointers[1451], &pointers[1452], &pointers[1453], &pointers[1454], &pointers[1455], &pointers[1456], &pointers[1457], &pointers[1458], &pointers[1459], &pointers[1460], &pointers[1461], &pointers[1462], &pointers[1463], &pointers[1464], &pointers[1465], &pointers[1466], &pointers[1467], &pointers[1468], &pointers[1469], &pointers[1470], &pointers[1471], &pointers[1472], &pointers[1473], &pointers[1474], &pointers[1475], &pointers[1476], &pointers[1477], &pointers[1478], &pointers[1479], &pointers[1480], &pointers[1481], &pointers[1482], &pointers[1483], &pointers[1484], &pointers[1485], &pointers[1486], &pointers[1487], &pointers[1488], &pointers[1489], &pointers[1490], &pointers[1491], &pointers[1492], &pointers[1493], &pointers[1494], &pointers[1495], &pointers[1496], &pointers[1497], &pointers[1498], &pointers[1499], &pointers[1500],
  &pointers[1501], &pointers[1502], &pointers[1503], &pointers[1504], &pointers[1505], &pointers[1506], &pointers[1507], &pointers[1508], &pointers[1509], &pointers[1510], &pointers[1511], &pointers[1512], &pointers[1513], &pointers[1514], &pointers[1515], &pointers[1516], &pointers[1517], &pointers[1518], &pointers[1519], &pointers[1520], &pointers[1521], &pointers[1522], &pointers[1523], &pointers[1524], &pointers[1525], &pointers[1526], &pointers[1527], &pointers[1528], &pointers[1529], &pointers[1530], &pointers[1531], &pointers[1532], &pointers[1533], &pointers[1534], &pointers[1535], &pointers[1536], &pointers[1537], &pointers[1538], &pointers[1539], &pointers[1540], &pointers[1541], &pointers[1542], &pointers[1543], &pointers[1544], &pointers[1545], &pointers[1546], &pointers[1547], &pointers[1548], &pointers[1549], &pointers[1550],
  &pointers[1551], &pointers[1552], &pointers[1553], &pointers[1554], &pointers[1555], &pointers[1556], &pointers[1557], &pointers[1558], &pointers[1559], &pointers[1560], &pointers[1561], &pointers[1562], &pointers[1563], &pointers[1564], &pointers[1565], &pointers[1566], &pointers[1567], &pointers[1568], &pointers[1569], &pointers[1570], &pointers[1571], &pointers[1572], &pointers[1573], &pointers[1574], &pointers[1575], &pointers[1576], &pointers[1577], &pointers[1578], &pointers[1579], &pointers[1580], &pointers[1581], &pointers[1582], &pointers[1583], &pointers[1584], &pointers[1585], &pointers[1586], &pointers[1587], &pointers[1588], &pointers[1589], &pointers[1590], &pointers[1591], &pointers[1592], &pointers[1593], &pointers[1594], &pointers[1595], &pointers[1596], &pointers[1597], &pointers[1598], &pointers[1599], &pointers[1600],
  &pointers[1601], &pointers[1602], &pointers[1603], &pointers[1604], &pointers[1605], &pointers[1606], &pointers[1607], &pointers[1608], &pointers[1609], &pointers[1610], &pointers[1611], &pointers[1612], &pointers[1613], &pointers[1614], &pointers[1615], &pointers[1616], &pointers[1617], &pointers[1618], &pointers[1619], &pointers[1620], &pointers[1621], &pointers[1622], &pointers[1623], &pointers[1624], &pointers[1625], &pointers[1626], &pointers[1627], &pointers[1628], &pointers[1629], &pointers[1630], &pointers[1631], &pointers[1632], &pointers[1633], &pointers[1634], &pointers[1635], &pointers[1636], &pointers[1637], &pointers[1638], &pointers[1639], &pointers[1640], &pointers[1641], &pointers[1642], &pointers[1643], &pointers[1644], &pointers[1645], &pointers[1646], &pointers[1647], &pointers[1648], &pointers[1649], &pointers[1650],
  &pointers[1651], &pointers[1652], &pointers[1653], &pointers[1654], &pointers[1655], &pointers[1656], &pointers[1657], &pointers[1658], &pointers[1659], &pointers[1660], &pointers[1661], &pointers[1662], &pointers[1663], &pointers[1664], &pointers[1665], &pointers[1666], &pointers[1667], &pointers[1668], &pointers[1669], &pointers[1670], &pointers[1671], &pointers[1672], &pointers[1673], &pointers[1674], &pointers[1675], &pointers[1676], &pointers[1677], &pointers[1678], &pointers[1679], &pointers[1680], &pointers[1681], &pointers[1682], &pointers[1683], &pointers[1684], &pointers[1685], &pointers[1686], &pointers[1687], &pointers[1688], &pointers[1689], &pointers[1690], &pointers[1691], &pointers[1692], &pointers[1693], &pointers[1694], &pointers[1695], &pointers[1696], &pointers[1697], &pointers[1698], &pointers[1699], &pointers[1700],
  &pointers[1701], &pointers[1702], &pointers[1703], &pointers[1704], &pointers[1705], &pointers[1706], &pointers[1707], &pointers[1708], &pointers[1709], &pointers[1710], &pointers[1711], &pointers[1712], &pointers[1713], &pointers[1714], &pointers[1715], &pointers[1716], &pointers[1717], &pointers[1718], &pointers[1719], &pointers[1720], &pointers[1721], &pointers[1722], &pointers[1723], &pointers[1724], &pointers[1725], &pointers[1726], &pointers[1727], &pointers[1728], &pointers[1729], &pointers[1730], &pointers[1731], &pointers[1732], &pointers[1733], &pointers[1734], &pointers[1735], &pointers[1736], &pointers[1737], &pointers[1738], &pointers[1739], &pointers[1740], &pointers[1741], &pointers[1742], &pointers[1743], &pointers[1744], &pointers[1745], &pointers[1746], &pointers[1747], &pointers[1748], &pointers[1749], &pointers[1750],
  &pointers[1751], &pointers[1752], &pointers[1753], &pointers[1754], &pointers[1755], &pointers[1756], &pointers[1757], &pointers[1758], &pointers[1759], &pointers[1760], &pointers[1761], &pointers[1762], &pointers[1763], &pointers[1764], &pointers[1765], &pointers[1766], &pointers[1767], &pointers[1768], &pointers[1769], &pointers[1770], &pointers[1771], &pointers[1772], &pointers[1773], &pointers[1774], &pointers[1775], &pointers[1776], &pointers[1777], &pointers[1778], &pointers[1779], &pointers[1780], &pointers[1781], &pointers[1782], &pointers[1783], &pointers[1784], &pointers[1785], &pointers[1786], &pointers[1787], &pointers[1788], &pointers[1789], &pointers[1790], &pointers[1791], &pointers[1792], &pointers[1793], &pointers[1794], &pointers[1795], &pointers[1796], &pointers[1797], &pointers[1798], &pointers[1799], &pointers[1800],
  &pointers[1801], &pointers[1802], &pointers[1803], &pointers[1804], &pointers[1805], &pointers[1806], &pointers[1807], &pointers[1808], &pointers[1809], &pointers[1810], &pointers[1811], &pointers[1812], &pointers[1813], &pointers[1814], &pointers[1815], &pointers[1816], &pointers[1817], &pointers[1818], &pointers[1819], &pointers[1820], &pointers[1821], &pointers[1822], &pointers[1823], &pointers[1824], &pointers[1825], &pointers[1826], &pointers[1827], &pointers[1828], &pointers[1829], &pointers[1830], &pointers[1831], &pointers[1832], &pointers[1833], &pointers[1834], &pointers[1835], &pointers[1836], &pointers[1837], &pointers[1838], &pointers[1839], &pointers[1840], &pointers[1841], &pointers[1842], &pointers[1843], &pointers[1844], &pointers[1845], &pointers[1846], &pointers[1847], &pointers[1848], &pointers[1849], &pointers[1850],
  &pointers[1851], &pointers[1852], &pointers[1853], &pointers[1854], &pointers[1855], &pointers[1856], &pointers[1857], &pointers[1858], &pointers[1859], &pointers[1860], &pointers[1861], &pointers[1862], &pointers[1863], &pointers[1864], &pointers[1865], &pointers[1866], &pointers[1867], &pointers[1868], &pointers[1869], &pointers[1870], &pointers[1871], &pointers[1872], &pointers[1873], &pointers[1874], &pointers[1875], &pointers[1876], &pointers[1877], &pointers[1878], &pointers[1879], &pointers[1880], &pointers[1881], &pointers[1882], &pointers[1883], &pointers[1884], &pointers[1885], &pointers[1886], &pointers[1887], &pointers[1888], &pointers[1889], &pointers[1890], &pointers[1891], &pointers[1892], &pointers[1893], &pointers[1894], &pointers[1895], &pointers[1896], &pointers[1897], &pointers[1898], &pointers[1899], &pointers[1900],
  &pointers[1901], &pointers[1902], &pointers[1903], &pointers[1904], &pointers[1905], &pointers[1906], &pointers[1907], &pointers[1908], &pointers[1909], &pointers[1910], &pointers[1911], &pointers[1912], &pointers[1913], &pointers[1914], &pointers[1915], &pointers[1916], &pointers[1917], &pointers[1918], &pointers[1919], &pointers[1920], &pointers[1921], &pointers[1922], &pointers[1923], &pointers[1924], &pointers[1925], &pointers[1926], &pointers[1927], &pointers[1928], &pointers[1929], &pointers[1930], &pointers[1931], &pointers[1932], &pointers[1933], &pointers[1934], &pointers[1935], &pointers[1936], &pointers[1937], &pointers[1938], &pointers[1939], &pointers[1940], &pointers[1941], &pointers[1942], &pointers[1943], &pointers[1944], &pointers[1945], &pointers[1946], &pointers[1947], &pointers[1948], &pointers[1949], &pointers[1950],
  &pointers[1951], &pointers[1952], &pointers[1953], &pointers[1954], &pointers[1955], &pointers[1956], &pointers[1957], &pointers[1958], &pointers[1959], &pointers[1960], &pointers[1961], &pointers[1962], &pointers[1963], &pointers[1964], &pointers[1965], &pointers[1966], &pointers[1967], &pointers[1968], &pointers[1969], &pointers[1970], &pointers[1971], &pointers[1972], &pointers[1973], &pointers[1974], &pointers[1975], &pointers[1976], &pointers[1977], &pointers[1978], &pointers[1979], &pointers[1980], &pointers[1981], &pointers[1982], &pointers[1983], &pointers[1984], &pointers[1985], &pointers[1986], &pointers[1987], &pointers[1988], &pointers[1989], &pointers[1990], &pointers[1991], &pointers[1992], &pointers[1993], &pointers[1994], &pointers[1995], &pointers[1996], &pointers[1997], &pointers[1998], &pointers[1999], NULL };
#endif
/* USER CODE END 0 */

int main(void)
{
  /* USER CODE BEGIN 1 */
  int time1 __attribute__((aligned (4))) = 0;
  int time2 __attribute__((aligned (4))) = 0;

  //void volatile **this_pp __attribute__((aligned (4))) = p0;
  //void volatile **this_pp __attribute__((aligned (4))) = &pointers[0];

  /* USER CODE END 1 */

  /* MCU Configuration--------------------------------------------------------*/

  /* Reset of all peripherals, Initializes the Flash interface and the Systick. */
  HAL_Init();

  /* Configure the system clock */
  SystemClock_Config();

  /* Initialize all configured peripherals */
  MX_GPIO_Init();
  MX_TIM2_Init();
  MX_USART1_UART_Init();
  /* USER CODE BEGIN 2 */
//  TIM2->CR1&=~TIM_CR1_DIR;

  HAL_TIM_Base_Start(&htim2);
  // enable update interrupts
  TIM2->DIER|=TIM_DIER_UIE;

////////////////////////////////////////////////////////////////////start counting time

  overflow_cnt = 0;
  time1 = TIM2->CNT;

  pointer_chase(&(pointers[0]));

  time2 = TIM2->CNT;
  ////////////////////////////////////////////////////////////////////end counting time
  tim_cnt = time2 -time1;
  execution_time = overflow_cnt*1000 + (double)tim_cnt/(1000);

  uint8_t msg[40] = {'\0'};

  sprintf(msg,"\n\rPointerChase:\n\r%d", (int)(execution_time*1000));
  HAL_UART_Transmit(&huart1, msg, sizeof(msg), 0xffff);

  //execution time is in ms

  /* USER CODE END 2 */

  /* Infinite loop */
  /* USER CODE BEGIN WHILE */
  int  i = 0;
  while (i<10)
  {
	  MX_TIM2_Init();
	  HAL_TIM_Base_Start(&htim2);
	  overflow_cnt = 0;
	  time1 = TIM2->CNT;

	  pointer_chase(&(pointers[0]));

	  time2 = TIM2->CNT;
	  ////////////////////////////////////////////////////////////////////end counting time
	  tim_cnt = time2 -time1;
	  execution_time = overflow_cnt*1000 + (double)tim_cnt/(1000);

	  uint8_t msg[40] = {'\0'};

	  sprintf(msg,"\n\r%dth: PointerChase:\n\r%d", i,(int)(execution_time*1000));
	  HAL_UART_Transmit(&huart1, msg, sizeof(msg), 0xffff);
	  i++;
    /* USER CODE END WHILE */

    /* USER CODE BEGIN 3 */
  }
  return 0;
  /* USER CODE END 3 */
}

void SystemClock_Config(void)
{
  RCC_OscInitTypeDef RCC_OscInitStruct = {0};
  RCC_ClkInitTypeDef RCC_ClkInitStruct = {0};
  RCC_PeriphCLKInitTypeDef PeriphClkInit = {0};

  /** Initializes the RCC Oscillators according to the specified parameters
  * in the RCC_OscInitTypeDef structure.
  */
  RCC_OscInitStruct.OscillatorType = RCC_OSCILLATORTYPE_HSE;
  RCC_OscInitStruct.HSEState = RCC_HSE_ON;
  RCC_OscInitStruct.HSEPredivValue = RCC_HSE_PREDIV_DIV1;
  RCC_OscInitStruct.HSIState = RCC_HSI_ON;
  RCC_OscInitStruct.PLL.PLLState = RCC_PLL_ON;
  RCC_OscInitStruct.PLL.PLLSource = RCC_PLLSOURCE_HSE;
  RCC_OscInitStruct.PLL.PLLMUL = RCC_PLL_MUL3;
  if (HAL_RCC_OscConfig(&RCC_OscInitStruct) != HAL_OK)
  {
    Error_Handler();
  }
  /** Initializes the CPU, AHB and APB buses clocks
  */
  RCC_ClkInitStruct.ClockType = RCC_CLOCKTYPE_HCLK|RCC_CLOCKTYPE_SYSCLK
                              |RCC_CLOCKTYPE_PCLK1|RCC_CLOCKTYPE_PCLK2;
  RCC_ClkInitStruct.SYSCLKSource = RCC_SYSCLKSOURCE_PLLCLK;
  RCC_ClkInitStruct.AHBCLKDivider = RCC_SYSCLK_DIV1;
  RCC_ClkInitStruct.APB1CLKDivider = RCC_HCLK_DIV2;
  RCC_ClkInitStruct.APB2CLKDivider = RCC_HCLK_DIV1;

  if (HAL_RCC_ClockConfig(&RCC_ClkInitStruct, FLASH_LATENCY_0) != HAL_OK)
  {
    Error_Handler();
  }
  PeriphClkInit.PeriphClockSelection = RCC_PERIPHCLK_USART1;
  PeriphClkInit.Usart1ClockSelection = RCC_USART1CLKSOURCE_PCLK2;
  if (HAL_RCCEx_PeriphCLKConfig(&PeriphClkInit) != HAL_OK)
  {
    Error_Handler();
  }
}

static void MX_TIM2_Init(void)
{

  TIM_ClockConfigTypeDef sClockSourceConfig = {0};
  TIM_MasterConfigTypeDef sMasterConfig = {0};

  htim2.Instance = TIM2;
  htim2.Init.Prescaler = (24-1);
  htim2.Init.CounterMode = TIM_COUNTERMODE_UP;
  htim2.Init.Period = (1000000-1);
  htim2.Init.ClockDivision = TIM_CLOCKDIVISION_DIV1;
  htim2.Init.AutoReloadPreload = TIM_AUTORELOAD_PRELOAD_DISABLE;
  if (HAL_TIM_Base_Init(&htim2) != HAL_OK)
  {
    Error_Handler();
  }
  sClockSourceConfig.ClockSource = TIM_CLOCKSOURCE_INTERNAL;
  if (HAL_TIM_ConfigClockSource(&htim2, &sClockSourceConfig) != HAL_OK)
  {
    Error_Handler();
  }
  sMasterConfig.MasterOutputTrigger = TIM_TRGO_RESET;
  sMasterConfig.MasterSlaveMode = TIM_MASTERSLAVEMODE_DISABLE;
  if (HAL_TIMEx_MasterConfigSynchronization(&htim2, &sMasterConfig) != HAL_OK)
  {
    Error_Handler();
  }

}

static void MX_USART1_UART_Init(void)
{

  huart1.Instance = USART1;
  huart1.Init.BaudRate = 38400;
  huart1.Init.WordLength = UART_WORDLENGTH_8B;
  huart1.Init.StopBits = UART_STOPBITS_1;
  huart1.Init.Parity = UART_PARITY_NONE;
  huart1.Init.Mode = UART_MODE_TX_RX;
  huart1.Init.HwFlowCtl = UART_HWCONTROL_NONE;
  huart1.Init.OverSampling = UART_OVERSAMPLING_16;
  huart1.Init.OneBitSampling = UART_ONE_BIT_SAMPLE_DISABLE;
  huart1.AdvancedInit.AdvFeatureInit = UART_ADVFEATURE_NO_INIT;
  if (HAL_UART_Init(&huart1) != HAL_OK)
  {
    Error_Handler();
  }

}

static void MX_GPIO_Init(void)
{

  /* GPIO Ports Clock Enable */
  __HAL_RCC_GPIOF_CLK_ENABLE();
  __HAL_RCC_GPIOC_CLK_ENABLE();

}

/* USER CODE BEGIN 4 */
void HAL_TIM_PeriodElapsedCallback(TIM_HandleTypeDef* htim)
{
	overflow_cnt++;

}

/* USER CODE END 4 */

void Error_Handler(void)
{
  __disable_irq();
  while (1)
  {
  }
}

/************************ (C) COPYRIGHT STMicroelectronics *****END OF FILE****/
